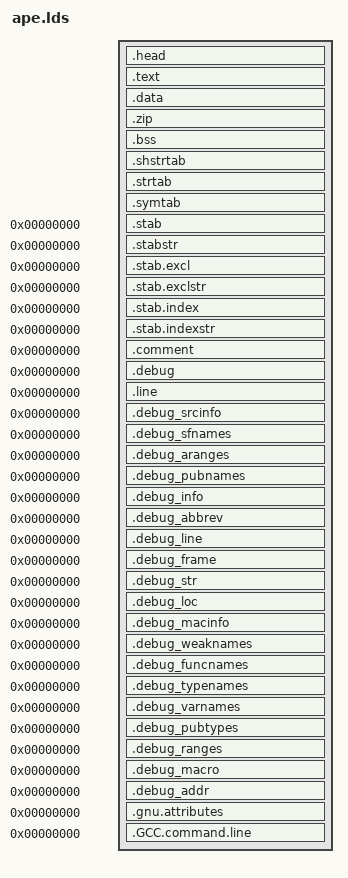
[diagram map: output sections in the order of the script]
ENTRY(_start)
PHDRS {
  Head PT_LOAD FLAGS(5);
  Rom PT_LOAD FLAGS(5);
  Ram PT_LOAD FLAGS(6);
  stack PT_GNU_STACK FLAGS(6);
}
SECTIONS {
  .head SEGMENT_START("text-segment", 0x400000) : AT(0x2000) {
    HIDDEN(_base = .);
    KEEP(*(.head))
    KEEP(*(.text.head))
    . = ALIGN(8);
    HIDDEN(ape_phdrs = .);
    KEEP(*(.elf.phdrs))
    HIDDEN(ape_phdrs_end = .);
    . = ALIGN(8);
    HIDDEN(ape_note = .);
    KEEP(*(.note.openbsd.ident))
    KEEP(*(.note.netbsd.ident))
    HIDDEN(ape_note_end = .);
    KEEP(*(.pe.header))
    HIDDEN(ape_pe_sections = .);
    KEEP(*(.pe.sections))
    HIDDEN(ape_pe_sections_end = .);
    KEEP(*(.macho))
    . = ALIGN(8);
    HIDDEN(ape_macho_end = .);
    KEEP(*(.ape.pad.head))
    . = ALIGN(((255 & 4) == 4) || ((255 & 2) == 2) ? 0x1000 : 16);
    HIDDEN(_ehead = .);
  } :Head
  .text . : {
    *(.text.real)
    KEEP(*(SORT_BY_NAME(.sort.text.real.*)))
    HIDDEN(_ereal = .);
    . += 1;
    *(.start)
    KEEP(*(.initprologue))
    KEEP(*(SORT_BY_NAME(.init.*)))
    KEEP(*(.init))
    KEEP(*(.initepilogue))
    KEEP(*(.pltprologue))
    *(.plt)
    KEEP(*(.pltepilogue))
    KEEP(*(.pltgotprologue))
    *(.plt.got)
    KEEP(*(.pltgotepilogue))
    *(.text.startup .text.startup.*)
    *(.text.exit .text.exit.*)
    *(.text.unlikely .text.*_unlikely .text.unlikely.*)
    *(SORT_BY_ALIGNMENT(.text.antiquity))
    *(SORT_BY_ALIGNMENT(.text.antiquity.*))
    KEEP(*(.textwindowsprologue))
    *(.text.windows)
    KEEP(*(.textwindowsepilogue))
    *(SORT_BY_ALIGNMENT(.text.modernity))
    *(SORT_BY_ALIGNMENT(.text.modernity.*))
    *(SORT_BY_ALIGNMENT(.text.hot))
    *(SORT_BY_ALIGNMENT(.text.hot.*))
    KEEP(*(.keep.text))
    *(.text .stub .text.*)
    KEEP(*(SORT_BY_NAME(.sort.text.*)))
    KEEP(*(.ape.pad.test));
    *(.test.unlikely)
    *(.test .test.*)
    KEEP(*(.ape.pad.privileged));
    . += . > 0 ? 1 : 0;
    HIDDEN(__privileged_start = .);
    . += . > 0 ? 1 : 0;
    *(.privileged)
    HIDDEN(__privileged_end = .);
    . += . > 0 ? 1 : 0;
    KEEP(*(.ape.pad.rodata));
    *(.rodata .rodata.*)
    *(.ubsan.types)
    *(.ubsan.data)
    KEEP(*(.commentprologue))
    KEEP(*(.comment))
    KEEP(*(.commentepilogue))
    KEEP(*(.idata.ro));
    KEEP(*(SORT_BY_NAME(.idata.ro.*)))
    . = ALIGN(8);
    PROVIDE_HIDDEN(__init_array_start = .);
    KEEP(*(SORT_BY_INIT_PRIORITY(.init_array.*)
           SORT_BY_INIT_PRIORITY(.ctors.*)))
    KEEP(*(.ctors))
    KEEP(*(.init_array))
    KEEP(*(.preinit_array))
    PROVIDE_HIDDEN(__init_array_end = .);
    . = ALIGN(8);
    PROVIDE_HIDDEN(__fini_array_start = .);
    KEEP(*(SORT_BY_INIT_PRIORITY(.fini_array.*)
           SORT_BY_INIT_PRIORITY(.dtors.*)))
    KEEP(*(.dtors))
    PROVIDE_HIDDEN(__fini_array_end = .);
    KEEP(*(.initroprologue))
    KEEP(*(SORT_BY_NAME(.initro.*)))
    KEEP(*(.initroepilogue))
    KEEP(*(SORT_BY_NAME(.sort.rodata.*)))
    KEEP(*(.ape.pad.text))
    . = ALIGN(0x1000);
    HIDDEN(_etext = .);
    PROVIDE_HIDDEN(etext = .);
  } :Rom
  .data . : {
    KEEP(*(.dataprologue))
    *(.data .data.*)
    KEEP(*(SORT_BY_NAME(.sort.data.*)))
    . += . > 0 ? 1 : 0;
    KEEP(*(.gotprologue))
    *(.got)
    KEEP(*(.gotepilogue))
    KEEP(*(.gotpltprologue))
    *(.got.plt)
    KEEP(*(.gotpltepilogue))
    . = ALIGN(8);
    KEEP(*(SORT_BY_NAME(.piro.relo.sort.*)))
    PROVIDE_HIDDEN(__relo_end = .);
    . = ALIGN(8);
    KEEP(*(SORT_BY_NAME(.piro.data.sort.*)))
    KEEP(*(.piro.pad.data))
    . = ALIGN(0x1000);
    HIDDEN(_edata = .);
    PROVIDE_HIDDEN(edata = .);
  } :Ram
  .zip . : {
    KEEP(*(SORT_BY_NAME(.zip.*)))
    HIDDEN(_ezip = .);
  }
  .bss ALIGN(8) : {
    KEEP(*(SORT_BY_NAME(.piro.bss.init.*)))
    *(.piro.bss)
    KEEP(*(SORT_BY_NAME(.piro.bss.sort.*)))
    HIDDEN(__piro_end = .);
    . += . > 0 ? 1 : 0;
    *(SORT_BY_ALIGNMENT(.bss))
    *(SORT_BY_ALIGNMENT(.bss.*))
    *(COMMON)
    KEEP(*(SORT_BY_NAME(.sort.bss.*)))
    . = ALIGN(0x10000);
    HIDDEN(_end = .);
    PROVIDE_HIDDEN(end = .);
  }
  .shstrtab : { *(.shstrtab) }
  .strtab : { *(.strtab) }
  .symtab : { *(.symtab) }
  .stab 0 : { *(.stab) }
  .stabstr 0 : { *(.stabstr) }
  .stab.excl 0 : { *(.stab.excl) }
  .stab.exclstr 0 : { *(.stab.exclstr) }
  .stab.index 0 : { *(.stab.index) }
  .stab.indexstr 0 : { *(.stab.indexstr) }
  .comment 0 : { *(.comment) }
  .debug 0 : { *(.debug) }
  .line 0 : { *(.line) }
  .debug_srcinfo 0 : { *(.debug_srcinfo) }
  .debug_sfnames 0 : { *(.debug_sfnames) }
  .debug_aranges 0 : { *(.debug_aranges) }
  .debug_pubnames 0 : { *(.debug_pubnames) }
  .debug_info 0 : { *(.debug_info .gnu.linkonce.wi.*) }
  .debug_abbrev 0 : { *(.debug_abbrev) }
  .debug_line 0 : { *(.debug_line .debug_line.* .debug_line_end ) }
  .debug_frame 0 : { *(.debug_frame) }
  .debug_str 0 : { *(.debug_str) }
  .debug_loc 0 : { *(.debug_loc) }
  .debug_macinfo 0 : { *(.debug_macinfo) }
  .debug_weaknames 0 : { *(.debug_weaknames) }
  .debug_funcnames 0 : { *(.debug_funcnames) }
  .debug_typenames 0 : { *(.debug_typenames) }
  .debug_varnames 0 : { *(.debug_varnames) }
  .debug_pubtypes 0 : { *(.debug_pubtypes) }
  .debug_ranges 0 : { *(.debug_ranges) }
  .debug_macro 0 : { *(.debug_macro) }
  .debug_addr 0 : { *(.debug_addr) }
  .gnu.attributes 0 : { KEEP(*(.gnu.attributes)) }
  .GCC.command.line 0 : { *(.GCC.command.line) }
  /DISCARD/ : {
    *(__mcount_loc)
    *(.discard)
    *(.yoink)
    *(.*)
  }
}
HIDDEN(ape_elf_entry = (_start)); HIDDEN(ape_elf_entry_bcs0 = (((((((_start) >> ((0)*8)) >> 0)&0x7) + 0x30) << 24) | ((((((_start) >> ((0)*8)) >> 3)&0x7) + 0x30) << 16) | (((((((_start) >> ((0)*8))&0xff) >> 6)&0x7) + 0x30) << 8) | 0x5c)); HIDDEN(ape_elf_entry_bcs1 = (((((((_start) >> ((1)*8)) >> 0)&0x7) + 0x30) << 24) | ((((((_start) >> ((1)*8)) >> 3)&0x7) + 0x30) << 16) | (((((((_start) >> ((1)*8))&0xff) >> 6)&0x7) + 0x30) << 8) | 0x5c)); HIDDEN(ape_elf_entry_bcs2 = (((((((_start) >> ((2)*8)) >> 0)&0x7) + 0x30) << 24) | ((((((_start) >> ((2)*8)) >> 3)&0x7) + 0x30) << 16) | (((((((_start) >> ((2)*8))&0xff) >> 6)&0x7) + 0x30) << 8) | 0x5c)); HIDDEN(ape_elf_entry_bcs3 = (((((((_start) >> ((3)*8)) >> 0)&0x7) + 0x30) << 24) | ((((((_start) >> ((3)*8)) >> 3)&0x7) + 0x30) << 16) | (((((((_start) >> ((3)*8))&0xff) >> 6)&0x7) + 0x30) << 8) | 0x5c)); HIDDEN(ape_elf_entry_bcs4 = (((((((_start) >> ((4)*8)) >> 0)&0x7) + 0x30) << 24) | ((((((_start) >> ((4)*8)) >> 3)&0x7) + 0x30) << 16) | (((((((_start) >> ((4)*8))&0xff) >> 6)&0x7) + 0x30) << 8) | 0x5c)); HIDDEN(ape_elf_entry_bcs5 = (((((((_start) >> ((5)*8)) >> 0)&0x7) + 0x30) << 24) | ((((((_start) >> ((5)*8)) >> 3)&0x7) + 0x30) << 16) | (((((((_start) >> ((5)*8))&0xff) >> 6)&0x7) + 0x30) << 8) | 0x5c)); HIDDEN(ape_elf_entry_bcs6 = (((((((_start) >> ((6)*8)) >> 0)&0x7) + 0x30) << 24) | ((((((_start) >> ((6)*8)) >> 3)&0x7) + 0x30) << 16) | (((((((_start) >> ((6)*8))&0xff) >> 6)&0x7) + 0x30) << 8) | 0x5c)); HIDDEN(ape_elf_entry_bcs7 = (((((((_start) >> ((7)*8)) >> 0)&0x7) + 0x30) << 24) | ((((((_start) >> ((7)*8)) >> 3)&0x7) + 0x30) << 16) | (((((((_start) >> ((7)*8))&0xff) >> 6)&0x7) + 0x30) << 8) | 0x5c));
HIDDEN(ape_elf_phoff = (((ape_phdrs) - (0x400000)))); HIDDEN(ape_elf_phoff_bcs0 = (((((((((ape_phdrs) - (0x400000))) >> ((0)*8)) >> 0)&0x7) + 0x30) << 24) | ((((((((ape_phdrs) - (0x400000))) >> ((0)*8)) >> 3)&0x7) + 0x30) << 16) | (((((((((ape_phdrs) - (0x400000))) >> ((0)*8))&0xff) >> 6)&0x7) + 0x30) << 8) | 0x5c)); HIDDEN(ape_elf_phoff_bcs1 = (((((((((ape_phdrs) - (0x400000))) >> ((1)*8)) >> 0)&0x7) + 0x30) << 24) | ((((((((ape_phdrs) - (0x400000))) >> ((1)*8)) >> 3)&0x7) + 0x30) << 16) | (((((((((ape_phdrs) - (0x400000))) >> ((1)*8))&0xff) >> 6)&0x7) + 0x30) << 8) | 0x5c)); HIDDEN(ape_elf_phoff_bcs2 = (((((((((ape_phdrs) - (0x400000))) >> ((2)*8)) >> 0)&0x7) + 0x30) << 24) | ((((((((ape_phdrs) - (0x400000))) >> ((2)*8)) >> 3)&0x7) + 0x30) << 16) | (((((((((ape_phdrs) - (0x400000))) >> ((2)*8))&0xff) >> 6)&0x7) + 0x30) << 8) | 0x5c)); HIDDEN(ape_elf_phoff_bcs3 = (((((((((ape_phdrs) - (0x400000))) >> ((3)*8)) >> 0)&0x7) + 0x30) << 24) | ((((((((ape_phdrs) - (0x400000))) >> ((3)*8)) >> 3)&0x7) + 0x30) << 16) | (((((((((ape_phdrs) - (0x400000))) >> ((3)*8))&0xff) >> 6)&0x7) + 0x30) << 8) | 0x5c)); HIDDEN(ape_elf_phoff_bcs4 = (((((((((ape_phdrs) - (0x400000))) >> ((4)*8)) >> 0)&0x7) + 0x30) << 24) | ((((((((ape_phdrs) - (0x400000))) >> ((4)*8)) >> 3)&0x7) + 0x30) << 16) | (((((((((ape_phdrs) - (0x400000))) >> ((4)*8))&0xff) >> 6)&0x7) + 0x30) << 8) | 0x5c)); HIDDEN(ape_elf_phoff_bcs5 = (((((((((ape_phdrs) - (0x400000))) >> ((5)*8)) >> 0)&0x7) + 0x30) << 24) | ((((((((ape_phdrs) - (0x400000))) >> ((5)*8)) >> 3)&0x7) + 0x30) << 16) | (((((((((ape_phdrs) - (0x400000))) >> ((5)*8))&0xff) >> 6)&0x7) + 0x30) << 8) | 0x5c)); HIDDEN(ape_elf_phoff_bcs6 = (((((((((ape_phdrs) - (0x400000))) >> ((6)*8)) >> 0)&0x7) + 0x30) << 24) | ((((((((ape_phdrs) - (0x400000))) >> ((6)*8)) >> 3)&0x7) + 0x30) << 16) | (((((((((ape_phdrs) - (0x400000))) >> ((6)*8))&0xff) >> 6)&0x7) + 0x30) << 8) | 0x5c)); HIDDEN(ape_elf_phoff_bcs7 = (((((((((ape_phdrs) - (0x400000))) >> ((7)*8)) >> 0)&0x7) + 0x30) << 24) | ((((((((ape_phdrs) - (0x400000))) >> ((7)*8)) >> 3)&0x7) + 0x30) << 16) | (((((((((ape_phdrs) - (0x400000))) >> ((7)*8))&0xff) >> 6)&0x7) + 0x30) << 8) | 0x5c));
HIDDEN(ape_elf_shoff = (0)); HIDDEN(ape_elf_shoff_bcs0 = (((((((0) >> ((0)*8)) >> 0)&0x7) + 0x30) << 24) | ((((((0) >> ((0)*8)) >> 3)&0x7) + 0x30) << 16) | (((((((0) >> ((0)*8))&0xff) >> 6)&0x7) + 0x30) << 8) | 0x5c)); HIDDEN(ape_elf_shoff_bcs1 = (((((((0) >> ((1)*8)) >> 0)&0x7) + 0x30) << 24) | ((((((0) >> ((1)*8)) >> 3)&0x7) + 0x30) << 16) | (((((((0) >> ((1)*8))&0xff) >> 6)&0x7) + 0x30) << 8) | 0x5c)); HIDDEN(ape_elf_shoff_bcs2 = (((((((0) >> ((2)*8)) >> 0)&0x7) + 0x30) << 24) | ((((((0) >> ((2)*8)) >> 3)&0x7) + 0x30) << 16) | (((((((0) >> ((2)*8))&0xff) >> 6)&0x7) + 0x30) << 8) | 0x5c)); HIDDEN(ape_elf_shoff_bcs3 = (((((((0) >> ((3)*8)) >> 0)&0x7) + 0x30) << 24) | ((((((0) >> ((3)*8)) >> 3)&0x7) + 0x30) << 16) | (((((((0) >> ((3)*8))&0xff) >> 6)&0x7) + 0x30) << 8) | 0x5c)); HIDDEN(ape_elf_shoff_bcs4 = (((((((0) >> ((4)*8)) >> 0)&0x7) + 0x30) << 24) | ((((((0) >> ((4)*8)) >> 3)&0x7) + 0x30) << 16) | (((((((0) >> ((4)*8))&0xff) >> 6)&0x7) + 0x30) << 8) | 0x5c)); HIDDEN(ape_elf_shoff_bcs5 = (((((((0) >> ((5)*8)) >> 0)&0x7) + 0x30) << 24) | ((((((0) >> ((5)*8)) >> 3)&0x7) + 0x30) << 16) | (((((((0) >> ((5)*8))&0xff) >> 6)&0x7) + 0x30) << 8) | 0x5c)); HIDDEN(ape_elf_shoff_bcs6 = (((((((0) >> ((6)*8)) >> 0)&0x7) + 0x30) << 24) | ((((((0) >> ((6)*8)) >> 3)&0x7) + 0x30) << 16) | (((((((0) >> ((6)*8))&0xff) >> 6)&0x7) + 0x30) << 8) | 0x5c)); HIDDEN(ape_elf_shoff_bcs7 = (((((((0) >> ((7)*8)) >> 0)&0x7) + 0x30) << 24) | ((((((0) >> ((7)*8)) >> 3)&0x7) + 0x30) << 16) | (((((((0) >> ((7)*8))&0xff) >> 6)&0x7) + 0x30) << 8) | 0x5c));
HIDDEN(ape_elf_phnum = ((ape_phdrs_end - ape_phdrs) / 56)); HIDDEN(ape_elf_phnum_bcs0 = ((((((((ape_phdrs_end - ape_phdrs) / 56) >> ((0)*8)) >> 0)&0x7) + 0x30) << 24) | (((((((ape_phdrs_end - ape_phdrs) / 56) >> ((0)*8)) >> 3)&0x7) + 0x30) << 16) | ((((((((ape_phdrs_end - ape_phdrs) / 56) >> ((0)*8))&0xff) >> 6)&0x7) + 0x30) << 8) | 0x5c)); HIDDEN(ape_elf_phnum_bcs1 = ((((((((ape_phdrs_end - ape_phdrs) / 56) >> ((1)*8)) >> 0)&0x7) + 0x30) << 24) | (((((((ape_phdrs_end - ape_phdrs) / 56) >> ((1)*8)) >> 3)&0x7) + 0x30) << 16) | ((((((((ape_phdrs_end - ape_phdrs) / 56) >> ((1)*8))&0xff) >> 6)&0x7) + 0x30) << 8) | 0x5c)); HIDDEN(ape_elf_phnum_bcs2 = ((((((((ape_phdrs_end - ape_phdrs) / 56) >> ((2)*8)) >> 0)&0x7) + 0x30) << 24) | (((((((ape_phdrs_end - ape_phdrs) / 56) >> ((2)*8)) >> 3)&0x7) + 0x30) << 16) | ((((((((ape_phdrs_end - ape_phdrs) / 56) >> ((2)*8))&0xff) >> 6)&0x7) + 0x30) << 8) | 0x5c)); HIDDEN(ape_elf_phnum_bcs3 = ((((((((ape_phdrs_end - ape_phdrs) / 56) >> ((3)*8)) >> 0)&0x7) + 0x30) << 24) | (((((((ape_phdrs_end - ape_phdrs) / 56) >> ((3)*8)) >> 3)&0x7) + 0x30) << 16) | ((((((((ape_phdrs_end - ape_phdrs) / 56) >> ((3)*8))&0xff) >> 6)&0x7) + 0x30) << 8) | 0x5c));
HIDDEN(ape_elf_shnum = (0)); HIDDEN(ape_elf_shnum_bcs0 = (((((((0) >> ((0)*8)) >> 0)&0x7) + 0x30) << 24) | ((((((0) >> ((0)*8)) >> 3)&0x7) + 0x30) << 16) | (((((((0) >> ((0)*8))&0xff) >> 6)&0x7) + 0x30) << 8) | 0x5c)); HIDDEN(ape_elf_shnum_bcs1 = (((((((0) >> ((1)*8)) >> 0)&0x7) + 0x30) << 24) | ((((((0) >> ((1)*8)) >> 3)&0x7) + 0x30) << 16) | (((((((0) >> ((1)*8))&0xff) >> 6)&0x7) + 0x30) << 8) | 0x5c)); HIDDEN(ape_elf_shnum_bcs2 = (((((((0) >> ((2)*8)) >> 0)&0x7) + 0x30) << 24) | ((((((0) >> ((2)*8)) >> 3)&0x7) + 0x30) << 16) | (((((((0) >> ((2)*8))&0xff) >> 6)&0x7) + 0x30) << 8) | 0x5c)); HIDDEN(ape_elf_shnum_bcs3 = (((((((0) >> ((3)*8)) >> 0)&0x7) + 0x30) << 24) | ((((((0) >> ((3)*8)) >> 3)&0x7) + 0x30) << 16) | (((((((0) >> ((3)*8))&0xff) >> 6)&0x7) + 0x30) << 8) | 0x5c));
HIDDEN(ape_elf_shstrndx = (0)); HIDDEN(ape_elf_shstrndx_bcs0 = (((((((0) >> ((0)*8)) >> 0)&0x7) + 0x30) << 24) | ((((((0) >> ((0)*8)) >> 3)&0x7) + 0x30) << 16) | (((((((0) >> ((0)*8))&0xff) >> 6)&0x7) + 0x30) << 8) | 0x5c)); HIDDEN(ape_elf_shstrndx_bcs1 = (((((((0) >> ((1)*8)) >> 0)&0x7) + 0x30) << 24) | ((((((0) >> ((1)*8)) >> 3)&0x7) + 0x30) << 16) | (((((((0) >> ((1)*8))&0xff) >> 6)&0x7) + 0x30) << 8) | 0x5c)); HIDDEN(ape_elf_shstrndx_bcs2 = (((((((0) >> ((2)*8)) >> 0)&0x7) + 0x30) << 24) | ((((((0) >> ((2)*8)) >> 3)&0x7) + 0x30) << 16) | (((((((0) >> ((2)*8))&0xff) >> 6)&0x7) + 0x30) << 8) | 0x5c)); HIDDEN(ape_elf_shstrndx_bcs3 = (((((((0) >> ((3)*8)) >> 0)&0x7) + 0x30) << 24) | ((((((0) >> ((3)*8)) >> 3)&0x7) + 0x30) << 16) | (((((((0) >> ((3)*8))&0xff) >> 6)&0x7) + 0x30) << 8) | 0x5c));
HIDDEN(__privileged_addr = ((__privileged_start) & -(0x1000)));
HIDDEN(__privileged_size = ((((__privileged_end) + (0x1000)-1) & -(0x1000)) -
                            ((__privileged_start) & -(0x1000))));
HIDDEN(ape_rom_offset = 0);
HIDDEN(ape_rom_vaddr = ADDR(.head));
HIDDEN(ape_rom_paddr = LOADADDR(.head));
HIDDEN(ape_rom_filesz = LOADADDR(.data) - ape_rom_paddr);
HIDDEN(ape_rom_memsz = ADDR(.data) - ADDR(.head));
HIDDEN(ape_rom_align = 0x1000);
HIDDEN(ape_rom_rva = ((ape_rom_vaddr) - (0x400000)));
HIDDEN(ape_ram_offset = ape_rom_offset + ape_rom_filesz);
HIDDEN(ape_ram_vaddr = ADDR(.data));
HIDDEN(ape_ram_paddr = LOADADDR(.data));
HIDDEN(ape_ram_filesz = SIZEOF(.data));
HIDDEN(ape_ram_memsz = ADDR(.bss) + SIZEOF(.bss) - ape_ram_vaddr);
HIDDEN(ape_ram_align = 0x1000);
HIDDEN(ape_ram_rva = ((ape_ram_vaddr) - (0x400000)));
HIDDEN(ape_stack_offset = ape_ram_offset + ape_ram_filesz);
HIDDEN(ape_stack_vaddr = 0x700000000000 - 0x100000);
HIDDEN(ape_stack_paddr = ape_ram_paddr + ape_ram_filesz);
HIDDEN(ape_stack_filesz = 0);
HIDDEN(ape_stack_memsz = 0x100000);
HIDDEN(ape_stack_align = 16);
HIDDEN(ape_note_offset = ape_rom_offset + (ape_note - ape_rom_vaddr));
HIDDEN(ape_note_vaddr = ape_note);
HIDDEN(ape_note_paddr = ape_rom_paddr + ape_note_offset);
HIDDEN(ape_note_filesz = ape_note_end - ape_note);
HIDDEN(ape_note_memsz = ape_note_filesz);
HIDDEN(ape_note_align = 8);
HIDDEN(ape_text_offset = ape_rom_offset + LOADADDR(.text) - ape_rom_paddr);
HIDDEN(ape_text_paddr = LOADADDR(.text));
HIDDEN(ape_text_vaddr = ADDR(.text));
HIDDEN(ape_text_filesz = SIZEOF(.text));
HIDDEN(ape_text_memsz = SIZEOF(.text));
HIDDEN(ape_text_align = 0x1000);
HIDDEN(ape_text_rva = ((ape_text_vaddr) - (0x400000)));
HIDDEN(ape_data_offset = ape_ram_offset + LOADADDR(.data) - ape_ram_paddr);
HIDDEN(ape_data_paddr = LOADADDR(.data));
HIDDEN(ape_data_vaddr = ADDR(.data));
HIDDEN(ape_data_filesz = SIZEOF(.data));
HIDDEN(ape_data_memsz = SIZEOF(.data));
HIDDEN(ape_data_align = 0x1000);
HIDDEN(ape_data_rva = ((ape_data_vaddr) - (0x400000)));
HIDDEN(ape_bss_offset = ape_ram_offset + LOADADDR(.bss) - ape_ram_paddr);
HIDDEN(ape_bss_paddr = LOADADDR(.bss));
HIDDEN(ape_bss_vaddr = ADDR(.bss));
HIDDEN(ape_bss_filesz = 0);
HIDDEN(ape_bss_memsz = SIZEOF(.bss));
HIDDEN(ape_bss_align = 0x1000);
HIDDEN(ape_macho_dd_skip_bcs0 = ((((ape_macho) - (0x400000)) / 8) < 10000 ? 0x20202020 : (((ape_macho) - (0x400000)) / 8) < 100000 ? 0x30202020 + (((((ape_macho) - (0x400000)) / 8) / 10000 % 10) << 24) : (((ape_macho) - (0x400000)) / 8) < 1000000 ? 0x30302020 + (((((ape_macho) - (0x400000)) / 8) / 10000 % 10) << 24) + (((((ape_macho) - (0x400000)) / 8) / 100000 % 10) << 16) : (((ape_macho) - (0x400000)) / 8) < 10000000 ? 0x30303020 + (((((ape_macho) - (0x400000)) / 8) / 10000 % 10) << 24) + (((((ape_macho) - (0x400000)) / 8) / 100000 % 10) << 16) + (((((ape_macho) - (0x400000)) / 8) / 1000000 % 10) << 8) : (((ape_macho) - (0x400000)) / 8) < 100000000 ? 0x30303030 + (((((ape_macho) - (0x400000)) / 8) / 10000 % 10) << 24) + (((((ape_macho) - (0x400000)) / 8) / 100000 % 10) << 16) + (((((ape_macho) - (0x400000)) / 8) / 1000000 % 10) << 8) + (((((ape_macho) - (0x400000)) / 8) / 10000000 % 10) << 0) : 0xffffffffffffffff)); HIDDEN(ape_macho_dd_skip_bcs1 = ((((ape_macho) - (0x400000)) / 8) == 0 ? 0x20202030 : (((ape_macho) - (0x400000)) / 8) < 10 ? 0x30202020 + (((((ape_macho) - (0x400000)) / 8) % 10) << 24) : (((ape_macho) - (0x400000)) / 8) < 100 ? 0x30302020 + (((((ape_macho) - (0x400000)) / 8) % 10) << 24) + (((((ape_macho) - (0x400000)) / 8) / 10 % 10) << 16) : (((ape_macho) - (0x400000)) / 8) < 1000 ? 0x30303020 + (((((ape_macho) - (0x400000)) / 8) % 10) << 24) + (((((ape_macho) - (0x400000)) / 8) / 10 % 10) << 16) + (((((ape_macho) - (0x400000)) / 8) / 100 % 10) << 8) : 0x30303030 + (((((ape_macho) - (0x400000)) / 8) % 10) << 24) + (((((ape_macho) - (0x400000)) / 8) / 10 % 10) << 16) + (((((ape_macho) - (0x400000)) / 8) / 100 % 10) << 8) + (((((ape_macho) - (0x400000)) / 8) / 1000 % 10) << 0)));
HIDDEN(ape_macho_dd_count_bcs0 = (((ape_macho_end - ape_macho) / 8) < 10000 ? 0x20202020 : ((ape_macho_end - ape_macho) / 8) < 100000 ? 0x30202020 + ((((ape_macho_end - ape_macho) / 8) / 10000 % 10) << 24) : ((ape_macho_end - ape_macho) / 8) < 1000000 ? 0x30302020 + ((((ape_macho_end - ape_macho) / 8) / 10000 % 10) << 24) + ((((ape_macho_end - ape_macho) / 8) / 100000 % 10) << 16) : ((ape_macho_end - ape_macho) / 8) < 10000000 ? 0x30303020 + ((((ape_macho_end - ape_macho) / 8) / 10000 % 10) << 24) + ((((ape_macho_end - ape_macho) / 8) / 100000 % 10) << 16) + ((((ape_macho_end - ape_macho) / 8) / 1000000 % 10) << 8) : ((ape_macho_end - ape_macho) / 8) < 100000000 ? 0x30303030 + ((((ape_macho_end - ape_macho) / 8) / 10000 % 10) << 24) + ((((ape_macho_end - ape_macho) / 8) / 100000 % 10) << 16) + ((((ape_macho_end - ape_macho) / 8) / 1000000 % 10) << 8) + ((((ape_macho_end - ape_macho) / 8) / 10000000 % 10) << 0) : 0xffffffffffffffff)); HIDDEN(ape_macho_dd_count_bcs1 = (((ape_macho_end - ape_macho) / 8) == 0 ? 0x20202030 : ((ape_macho_end - ape_macho) / 8) < 10 ? 0x30202020 + ((((ape_macho_end - ape_macho) / 8) % 10) << 24) : ((ape_macho_end - ape_macho) / 8) < 100 ? 0x30302020 + ((((ape_macho_end - ape_macho) / 8) % 10) << 24) + ((((ape_macho_end - ape_macho) / 8) / 10 % 10) << 16) : ((ape_macho_end - ape_macho) / 8) < 1000 ? 0x30303020 + ((((ape_macho_end - ape_macho) / 8) % 10) << 24) + ((((ape_macho_end - ape_macho) / 8) / 10 % 10) << 16) + ((((ape_macho_end - ape_macho) / 8) / 100 % 10) << 8) : 0x30303030 + ((((ape_macho_end - ape_macho) / 8) % 10) << 24) + ((((ape_macho_end - ape_macho) / 8) / 10 % 10) << 16) + ((((ape_macho_end - ape_macho) / 8) / 100 % 10) << 8) + ((((ape_macho_end - ape_macho) / 8) / 1000 % 10) << 0)));
HIDDEN(ape_pe_offset = (ape_pe - ape_mz)); HIDDEN(ape_pe_offset_bcs0 = (((((((ape_pe - ape_mz) >> ((0)*8)) >> 0)&0x7) + 0x30) << 24) | ((((((ape_pe - ape_mz) >> ((0)*8)) >> 3)&0x7) + 0x30) << 16) | (((((((ape_pe - ape_mz) >> ((0)*8))&0xff) >> 6)&0x7) + 0x30) << 8) | 0x5c)); HIDDEN(ape_pe_offset_bcs1 = (((((((ape_pe - ape_mz) >> ((1)*8)) >> 0)&0x7) + 0x30) << 24) | ((((((ape_pe - ape_mz) >> ((1)*8)) >> 3)&0x7) + 0x30) << 16) | (((((((ape_pe - ape_mz) >> ((1)*8))&0xff) >> 6)&0x7) + 0x30) << 8) | 0x5c)); HIDDEN(ape_pe_offset_bcs2 = (((((((ape_pe - ape_mz) >> ((2)*8)) >> 0)&0x7) + 0x30) << 24) | ((((((ape_pe - ape_mz) >> ((2)*8)) >> 3)&0x7) + 0x30) << 16) | (((((((ape_pe - ape_mz) >> ((2)*8))&0xff) >> 6)&0x7) + 0x30) << 8) | 0x5c)); HIDDEN(ape_pe_offset_bcs3 = (((((((ape_pe - ape_mz) >> ((3)*8)) >> 0)&0x7) + 0x30) << 24) | ((((((ape_pe - ape_mz) >> ((3)*8)) >> 3)&0x7) + 0x30) << 16) | (((((((ape_pe - ape_mz) >> ((3)*8))&0xff) >> 6)&0x7) + 0x30) << 8) | 0x5c));
HIDDEN(ape_pe_optsz = ape_pe_sections - (ape_pe + 24));
HIDDEN(ape_pe_shnum = (ape_pe_sections_end - ape_pe_sections) / 40);
HIDDEN(ape_pe_base = 0x400000);
HIDDEN(ape_idata = (((255 & 4) == 4) && !DEFINED(EfiMain)) ? ((ape_idata_iat) - (0x400000)) : 0);
HIDDEN(ape_idata_iatsize = (((255 & 4) == 4) && !DEFINED(EfiMain)) ? ape_idata_iatend - ape_idata_iat : 0);
HIDDEN(ape_idata = (((255 & 4) == 4) && !DEFINED(EfiMain)) ? ((ape_idata_idt) - (0x400000)) : 0);
HIDDEN(ape_idata_idtsize = (((255 & 4) == 4) && !DEFINED(EfiMain)) ? ape_idata_idtend - ape_idata_idt : 0);
HIDDEN(v_ntversion = (((255 & 4) == 4) && !DEFINED(EfiMain)) ? 6 : 1);
HIDDEN(v_ntdllchar = (((255 & 4) == 4) && !DEFINED(EfiMain)) ? 288 : 0);
HIDDEN(v_ntsubversion = (((255 & 4) == 4) && !DEFINED(EfiMain)) ? 6 : 5);
HIDDEN(v_ntsubsystem = ((((255 & 4) == 4) && !DEFINED(EfiMain))
                        ? (DEFINED(GetMessage)
                           ? 2
                           : 3)
                        : 10));
HIDDEN(ape_pe_entry = (((255 & 4) == 4) && !DEFINED(EfiMain)) ? WinMain : EfiMain);
HIDDEN(v_ape_realsectors =
           (((((((_edata) - (0x400000))) + (4096)-1) & -(4096))) > (0x70000 - 0x2000) ? (0x70000 - 0x2000) : ((((((_edata) - (0x400000))) + (4096)-1) & -(4096)))) / 512);
HIDDEN(v_ape_realpages = v_ape_realsectors / (4096 / 512));
HIDDEN(v_ape_highsectors =
           ((((((_edata) - (0x400000))) + (512)-1) & -(512)) / 512) - v_ape_realsectors);
HIDDEN(v_zip_cdoffset = DEFINED(__zip_start) ? __zip_start - 0x400000 : 0);;
HIDDEN(v_zip_cdirsize = DEFINED(__zip_start) ? __zip_end - __zip_start : 0);;
ASSERT(v_zip_cdirsize % (((46 + 248) + (2)-1) & -(2)) == 0, "bad zip cdir");
HIDDEN(v_zip_records = DEFINED(__zip_start) ? v_zip_cdirsize / (((46 + 248) + (2)-1) & -(2)) : 0);;
HIDDEN(v_zip_commentsize = DEFINED(__zip_start) ? _ezip - __zip_end - 22 : 0);;
HIDDEN(ape_uuid1 = 88172645463325252);
HIDDEN(ape_uuid2 = 88172645463325252);
ape_uuid1 = ((ape_uuid1 | (ape_bss_align >> 12)) - (ape_uuid1 & (ape_bss_align >> 12))); ape_uuid1 = ((ape_uuid1 | (ape_bss_align << 25)) - (ape_uuid1 & (ape_bss_align << 25))); ape_uuid1 = ((ape_uuid1 | (ape_bss_align >> 27)) - (ape_uuid1 & (ape_bss_align >> 27))); ape_uuid1 = (ape_uuid1 + (ape_bss_align >> 000) & 0xFF) * 0x9e3779b9925d4c17; ape_uuid1 = (ape_uuid1 + (ape_bss_align >> 010) & 0xFF) * 0x9e3779b9925d4c17; ape_uuid1 = (ape_uuid1 + (ape_bss_align >> 020) & 0xFF) * 0x9e3779b9925d4c17; ape_uuid1 = (ape_uuid1 + (ape_bss_align >> 030) & 0xFF) * 0x9e3779b9925d4c17; ape_uuid2 = ((ape_uuid2 | (ape_bss_align >> 12)) - (ape_uuid2 & (ape_bss_align >> 12))); ape_uuid2 = ((ape_uuid2 | (ape_bss_align << 25)) - (ape_uuid2 & (ape_bss_align << 25))); ape_uuid2 = ((ape_uuid2 | (ape_bss_align >> 27)) - (ape_uuid2 & (ape_bss_align >> 27))); ape_uuid2 = (ape_uuid2 + (ape_bss_align >> 000) & 0xFF) * 0x9e3779b9925d4c17; ape_uuid2 = (ape_uuid2 + (ape_bss_align >> 010) & 0xFF) * 0x9e3779b9925d4c17; ape_uuid2 = (ape_uuid2 + (ape_bss_align >> 020) & 0xFF) * 0x9e3779b9925d4c17; ape_uuid2 = (ape_uuid2 + (ape_bss_align >> 030) & 0xFF) * 0x9e3779b9925d4c17;
ape_uuid1 = ((ape_uuid1 | (ape_bss_filesz >> 12)) - (ape_uuid1 & (ape_bss_filesz >> 12))); ape_uuid1 = ((ape_uuid1 | (ape_bss_filesz << 25)) - (ape_uuid1 & (ape_bss_filesz << 25))); ape_uuid1 = ((ape_uuid1 | (ape_bss_filesz >> 27)) - (ape_uuid1 & (ape_bss_filesz >> 27))); ape_uuid1 = (ape_uuid1 + (ape_bss_filesz >> 000) & 0xFF) * 0x9e3779b9925d4c17; ape_uuid1 = (ape_uuid1 + (ape_bss_filesz >> 010) & 0xFF) * 0x9e3779b9925d4c17; ape_uuid1 = (ape_uuid1 + (ape_bss_filesz >> 020) & 0xFF) * 0x9e3779b9925d4c17; ape_uuid1 = (ape_uuid1 + (ape_bss_filesz >> 030) & 0xFF) * 0x9e3779b9925d4c17; ape_uuid2 = ((ape_uuid2 | (ape_bss_filesz >> 12)) - (ape_uuid2 & (ape_bss_filesz >> 12))); ape_uuid2 = ((ape_uuid2 | (ape_bss_filesz << 25)) - (ape_uuid2 & (ape_bss_filesz << 25))); ape_uuid2 = ((ape_uuid2 | (ape_bss_filesz >> 27)) - (ape_uuid2 & (ape_bss_filesz >> 27))); ape_uuid2 = (ape_uuid2 + (ape_bss_filesz >> 000) & 0xFF) * 0x9e3779b9925d4c17; ape_uuid2 = (ape_uuid2 + (ape_bss_filesz >> 010) & 0xFF) * 0x9e3779b9925d4c17; ape_uuid2 = (ape_uuid2 + (ape_bss_filesz >> 020) & 0xFF) * 0x9e3779b9925d4c17; ape_uuid2 = (ape_uuid2 + (ape_bss_filesz >> 030) & 0xFF) * 0x9e3779b9925d4c17;
ape_uuid1 = ((ape_uuid1 | (ape_bss_memsz >> 12)) - (ape_uuid1 & (ape_bss_memsz >> 12))); ape_uuid1 = ((ape_uuid1 | (ape_bss_memsz << 25)) - (ape_uuid1 & (ape_bss_memsz << 25))); ape_uuid1 = ((ape_uuid1 | (ape_bss_memsz >> 27)) - (ape_uuid1 & (ape_bss_memsz >> 27))); ape_uuid1 = (ape_uuid1 + (ape_bss_memsz >> 000) & 0xFF) * 0x9e3779b9925d4c17; ape_uuid1 = (ape_uuid1 + (ape_bss_memsz >> 010) & 0xFF) * 0x9e3779b9925d4c17; ape_uuid1 = (ape_uuid1 + (ape_bss_memsz >> 020) & 0xFF) * 0x9e3779b9925d4c17; ape_uuid1 = (ape_uuid1 + (ape_bss_memsz >> 030) & 0xFF) * 0x9e3779b9925d4c17; ape_uuid2 = ((ape_uuid2 | (ape_bss_memsz >> 12)) - (ape_uuid2 & (ape_bss_memsz >> 12))); ape_uuid2 = ((ape_uuid2 | (ape_bss_memsz << 25)) - (ape_uuid2 & (ape_bss_memsz << 25))); ape_uuid2 = ((ape_uuid2 | (ape_bss_memsz >> 27)) - (ape_uuid2 & (ape_bss_memsz >> 27))); ape_uuid2 = (ape_uuid2 + (ape_bss_memsz >> 000) & 0xFF) * 0x9e3779b9925d4c17; ape_uuid2 = (ape_uuid2 + (ape_bss_memsz >> 010) & 0xFF) * 0x9e3779b9925d4c17; ape_uuid2 = (ape_uuid2 + (ape_bss_memsz >> 020) & 0xFF) * 0x9e3779b9925d4c17; ape_uuid2 = (ape_uuid2 + (ape_bss_memsz >> 030) & 0xFF) * 0x9e3779b9925d4c17;
ape_uuid1 = ((ape_uuid1 | (ape_bss_offset >> 12)) - (ape_uuid1 & (ape_bss_offset >> 12))); ape_uuid1 = ((ape_uuid1 | (ape_bss_offset << 25)) - (ape_uuid1 & (ape_bss_offset << 25))); ape_uuid1 = ((ape_uuid1 | (ape_bss_offset >> 27)) - (ape_uuid1 & (ape_bss_offset >> 27))); ape_uuid1 = (ape_uuid1 + (ape_bss_offset >> 000) & 0xFF) * 0x9e3779b9925d4c17; ape_uuid1 = (ape_uuid1 + (ape_bss_offset >> 010) & 0xFF) * 0x9e3779b9925d4c17; ape_uuid1 = (ape_uuid1 + (ape_bss_offset >> 020) & 0xFF) * 0x9e3779b9925d4c17; ape_uuid1 = (ape_uuid1 + (ape_bss_offset >> 030) & 0xFF) * 0x9e3779b9925d4c17; ape_uuid2 = ((ape_uuid2 | (ape_bss_offset >> 12)) - (ape_uuid2 & (ape_bss_offset >> 12))); ape_uuid2 = ((ape_uuid2 | (ape_bss_offset << 25)) - (ape_uuid2 & (ape_bss_offset << 25))); ape_uuid2 = ((ape_uuid2 | (ape_bss_offset >> 27)) - (ape_uuid2 & (ape_bss_offset >> 27))); ape_uuid2 = (ape_uuid2 + (ape_bss_offset >> 000) & 0xFF) * 0x9e3779b9925d4c17; ape_uuid2 = (ape_uuid2 + (ape_bss_offset >> 010) & 0xFF) * 0x9e3779b9925d4c17; ape_uuid2 = (ape_uuid2 + (ape_bss_offset >> 020) & 0xFF) * 0x9e3779b9925d4c17; ape_uuid2 = (ape_uuid2 + (ape_bss_offset >> 030) & 0xFF) * 0x9e3779b9925d4c17;
ape_uuid1 = ((ape_uuid1 | (ape_bss_paddr >> 12)) - (ape_uuid1 & (ape_bss_paddr >> 12))); ape_uuid1 = ((ape_uuid1 | (ape_bss_paddr << 25)) - (ape_uuid1 & (ape_bss_paddr << 25))); ape_uuid1 = ((ape_uuid1 | (ape_bss_paddr >> 27)) - (ape_uuid1 & (ape_bss_paddr >> 27))); ape_uuid1 = (ape_uuid1 + (ape_bss_paddr >> 000) & 0xFF) * 0x9e3779b9925d4c17; ape_uuid1 = (ape_uuid1 + (ape_bss_paddr >> 010) & 0xFF) * 0x9e3779b9925d4c17; ape_uuid1 = (ape_uuid1 + (ape_bss_paddr >> 020) & 0xFF) * 0x9e3779b9925d4c17; ape_uuid1 = (ape_uuid1 + (ape_bss_paddr >> 030) & 0xFF) * 0x9e3779b9925d4c17; ape_uuid2 = ((ape_uuid2 | (ape_bss_paddr >> 12)) - (ape_uuid2 & (ape_bss_paddr >> 12))); ape_uuid2 = ((ape_uuid2 | (ape_bss_paddr << 25)) - (ape_uuid2 & (ape_bss_paddr << 25))); ape_uuid2 = ((ape_uuid2 | (ape_bss_paddr >> 27)) - (ape_uuid2 & (ape_bss_paddr >> 27))); ape_uuid2 = (ape_uuid2 + (ape_bss_paddr >> 000) & 0xFF) * 0x9e3779b9925d4c17; ape_uuid2 = (ape_uuid2 + (ape_bss_paddr >> 010) & 0xFF) * 0x9e3779b9925d4c17; ape_uuid2 = (ape_uuid2 + (ape_bss_paddr >> 020) & 0xFF) * 0x9e3779b9925d4c17; ape_uuid2 = (ape_uuid2 + (ape_bss_paddr >> 030) & 0xFF) * 0x9e3779b9925d4c17;
ape_uuid1 = ((ape_uuid1 | (ape_data_filesz >> 12)) - (ape_uuid1 & (ape_data_filesz >> 12))); ape_uuid1 = ((ape_uuid1 | (ape_data_filesz << 25)) - (ape_uuid1 & (ape_data_filesz << 25))); ape_uuid1 = ((ape_uuid1 | (ape_data_filesz >> 27)) - (ape_uuid1 & (ape_data_filesz >> 27))); ape_uuid1 = (ape_uuid1 + (ape_data_filesz >> 000) & 0xFF) * 0x9e3779b9925d4c17; ape_uuid1 = (ape_uuid1 + (ape_data_filesz >> 010) & 0xFF) * 0x9e3779b9925d4c17; ape_uuid1 = (ape_uuid1 + (ape_data_filesz >> 020) & 0xFF) * 0x9e3779b9925d4c17; ape_uuid1 = (ape_uuid1 + (ape_data_filesz >> 030) & 0xFF) * 0x9e3779b9925d4c17; ape_uuid2 = ((ape_uuid2 | (ape_data_filesz >> 12)) - (ape_uuid2 & (ape_data_filesz >> 12))); ape_uuid2 = ((ape_uuid2 | (ape_data_filesz << 25)) - (ape_uuid2 & (ape_data_filesz << 25))); ape_uuid2 = ((ape_uuid2 | (ape_data_filesz >> 27)) - (ape_uuid2 & (ape_data_filesz >> 27))); ape_uuid2 = (ape_uuid2 + (ape_data_filesz >> 000) & 0xFF) * 0x9e3779b9925d4c17; ape_uuid2 = (ape_uuid2 + (ape_data_filesz >> 010) & 0xFF) * 0x9e3779b9925d4c17; ape_uuid2 = (ape_uuid2 + (ape_data_filesz >> 020) & 0xFF) * 0x9e3779b9925d4c17; ape_uuid2 = (ape_uuid2 + (ape_data_filesz >> 030) & 0xFF) * 0x9e3779b9925d4c17;
ape_uuid1 = ((ape_uuid1 | (ape_data_memsz >> 12)) - (ape_uuid1 & (ape_data_memsz >> 12))); ape_uuid1 = ((ape_uuid1 | (ape_data_memsz << 25)) - (ape_uuid1 & (ape_data_memsz << 25))); ape_uuid1 = ((ape_uuid1 | (ape_data_memsz >> 27)) - (ape_uuid1 & (ape_data_memsz >> 27))); ape_uuid1 = (ape_uuid1 + (ape_data_memsz >> 000) & 0xFF) * 0x9e3779b9925d4c17; ape_uuid1 = (ape_uuid1 + (ape_data_memsz >> 010) & 0xFF) * 0x9e3779b9925d4c17; ape_uuid1 = (ape_uuid1 + (ape_data_memsz >> 020) & 0xFF) * 0x9e3779b9925d4c17; ape_uuid1 = (ape_uuid1 + (ape_data_memsz >> 030) & 0xFF) * 0x9e3779b9925d4c17; ape_uuid2 = ((ape_uuid2 | (ape_data_memsz >> 12)) - (ape_uuid2 & (ape_data_memsz >> 12))); ape_uuid2 = ((ape_uuid2 | (ape_data_memsz << 25)) - (ape_uuid2 & (ape_data_memsz << 25))); ape_uuid2 = ((ape_uuid2 | (ape_data_memsz >> 27)) - (ape_uuid2 & (ape_data_memsz >> 27))); ape_uuid2 = (ape_uuid2 + (ape_data_memsz >> 000) & 0xFF) * 0x9e3779b9925d4c17; ape_uuid2 = (ape_uuid2 + (ape_data_memsz >> 010) & 0xFF) * 0x9e3779b9925d4c17; ape_uuid2 = (ape_uuid2 + (ape_data_memsz >> 020) & 0xFF) * 0x9e3779b9925d4c17; ape_uuid2 = (ape_uuid2 + (ape_data_memsz >> 030) & 0xFF) * 0x9e3779b9925d4c17;
ape_uuid1 = ((ape_uuid1 | (ape_data_offset >> 12)) - (ape_uuid1 & (ape_data_offset >> 12))); ape_uuid1 = ((ape_uuid1 | (ape_data_offset << 25)) - (ape_uuid1 & (ape_data_offset << 25))); ape_uuid1 = ((ape_uuid1 | (ape_data_offset >> 27)) - (ape_uuid1 & (ape_data_offset >> 27))); ape_uuid1 = (ape_uuid1 + (ape_data_offset >> 000) & 0xFF) * 0x9e3779b9925d4c17; ape_uuid1 = (ape_uuid1 + (ape_data_offset >> 010) & 0xFF) * 0x9e3779b9925d4c17; ape_uuid1 = (ape_uuid1 + (ape_data_offset >> 020) & 0xFF) * 0x9e3779b9925d4c17; ape_uuid1 = (ape_uuid1 + (ape_data_offset >> 030) & 0xFF) * 0x9e3779b9925d4c17; ape_uuid2 = ((ape_uuid2 | (ape_data_offset >> 12)) - (ape_uuid2 & (ape_data_offset >> 12))); ape_uuid2 = ((ape_uuid2 | (ape_data_offset << 25)) - (ape_uuid2 & (ape_data_offset << 25))); ape_uuid2 = ((ape_uuid2 | (ape_data_offset >> 27)) - (ape_uuid2 & (ape_data_offset >> 27))); ape_uuid2 = (ape_uuid2 + (ape_data_offset >> 000) & 0xFF) * 0x9e3779b9925d4c17; ape_uuid2 = (ape_uuid2 + (ape_data_offset >> 010) & 0xFF) * 0x9e3779b9925d4c17; ape_uuid2 = (ape_uuid2 + (ape_data_offset >> 020) & 0xFF) * 0x9e3779b9925d4c17; ape_uuid2 = (ape_uuid2 + (ape_data_offset >> 030) & 0xFF) * 0x9e3779b9925d4c17;
ape_uuid1 = ((ape_uuid1 | (ape_data_paddr >> 12)) - (ape_uuid1 & (ape_data_paddr >> 12))); ape_uuid1 = ((ape_uuid1 | (ape_data_paddr << 25)) - (ape_uuid1 & (ape_data_paddr << 25))); ape_uuid1 = ((ape_uuid1 | (ape_data_paddr >> 27)) - (ape_uuid1 & (ape_data_paddr >> 27))); ape_uuid1 = (ape_uuid1 + (ape_data_paddr >> 000) & 0xFF) * 0x9e3779b9925d4c17; ape_uuid1 = (ape_uuid1 + (ape_data_paddr >> 010) & 0xFF) * 0x9e3779b9925d4c17; ape_uuid1 = (ape_uuid1 + (ape_data_paddr >> 020) & 0xFF) * 0x9e3779b9925d4c17; ape_uuid1 = (ape_uuid1 + (ape_data_paddr >> 030) & 0xFF) * 0x9e3779b9925d4c17; ape_uuid2 = ((ape_uuid2 | (ape_data_paddr >> 12)) - (ape_uuid2 & (ape_data_paddr >> 12))); ape_uuid2 = ((ape_uuid2 | (ape_data_paddr << 25)) - (ape_uuid2 & (ape_data_paddr << 25))); ape_uuid2 = ((ape_uuid2 | (ape_data_paddr >> 27)) - (ape_uuid2 & (ape_data_paddr >> 27))); ape_uuid2 = (ape_uuid2 + (ape_data_paddr >> 000) & 0xFF) * 0x9e3779b9925d4c17; ape_uuid2 = (ape_uuid2 + (ape_data_paddr >> 010) & 0xFF) * 0x9e3779b9925d4c17; ape_uuid2 = (ape_uuid2 + (ape_data_paddr >> 020) & 0xFF) * 0x9e3779b9925d4c17; ape_uuid2 = (ape_uuid2 + (ape_data_paddr >> 030) & 0xFF) * 0x9e3779b9925d4c17;
ape_uuid1 = ((ape_uuid1 | (ape_data_rva >> 12)) - (ape_uuid1 & (ape_data_rva >> 12))); ape_uuid1 = ((ape_uuid1 | (ape_data_rva << 25)) - (ape_uuid1 & (ape_data_rva << 25))); ape_uuid1 = ((ape_uuid1 | (ape_data_rva >> 27)) - (ape_uuid1 & (ape_data_rva >> 27))); ape_uuid1 = (ape_uuid1 + (ape_data_rva >> 000) & 0xFF) * 0x9e3779b9925d4c17; ape_uuid1 = (ape_uuid1 + (ape_data_rva >> 010) & 0xFF) * 0x9e3779b9925d4c17; ape_uuid1 = (ape_uuid1 + (ape_data_rva >> 020) & 0xFF) * 0x9e3779b9925d4c17; ape_uuid1 = (ape_uuid1 + (ape_data_rva >> 030) & 0xFF) * 0x9e3779b9925d4c17; ape_uuid2 = ((ape_uuid2 | (ape_data_rva >> 12)) - (ape_uuid2 & (ape_data_rva >> 12))); ape_uuid2 = ((ape_uuid2 | (ape_data_rva << 25)) - (ape_uuid2 & (ape_data_rva << 25))); ape_uuid2 = ((ape_uuid2 | (ape_data_rva >> 27)) - (ape_uuid2 & (ape_data_rva >> 27))); ape_uuid2 = (ape_uuid2 + (ape_data_rva >> 000) & 0xFF) * 0x9e3779b9925d4c17; ape_uuid2 = (ape_uuid2 + (ape_data_rva >> 010) & 0xFF) * 0x9e3779b9925d4c17; ape_uuid2 = (ape_uuid2 + (ape_data_rva >> 020) & 0xFF) * 0x9e3779b9925d4c17; ape_uuid2 = (ape_uuid2 + (ape_data_rva >> 030) & 0xFF) * 0x9e3779b9925d4c17;
ape_uuid1 = ((ape_uuid1 | (ape_data_vaddr >> 12)) - (ape_uuid1 & (ape_data_vaddr >> 12))); ape_uuid1 = ((ape_uuid1 | (ape_data_vaddr << 25)) - (ape_uuid1 & (ape_data_vaddr << 25))); ape_uuid1 = ((ape_uuid1 | (ape_data_vaddr >> 27)) - (ape_uuid1 & (ape_data_vaddr >> 27))); ape_uuid1 = (ape_uuid1 + (ape_data_vaddr >> 000) & 0xFF) * 0x9e3779b9925d4c17; ape_uuid1 = (ape_uuid1 + (ape_data_vaddr >> 010) & 0xFF) * 0x9e3779b9925d4c17; ape_uuid1 = (ape_uuid1 + (ape_data_vaddr >> 020) & 0xFF) * 0x9e3779b9925d4c17; ape_uuid1 = (ape_uuid1 + (ape_data_vaddr >> 030) & 0xFF) * 0x9e3779b9925d4c17; ape_uuid2 = ((ape_uuid2 | (ape_data_vaddr >> 12)) - (ape_uuid2 & (ape_data_vaddr >> 12))); ape_uuid2 = ((ape_uuid2 | (ape_data_vaddr << 25)) - (ape_uuid2 & (ape_data_vaddr << 25))); ape_uuid2 = ((ape_uuid2 | (ape_data_vaddr >> 27)) - (ape_uuid2 & (ape_data_vaddr >> 27))); ape_uuid2 = (ape_uuid2 + (ape_data_vaddr >> 000) & 0xFF) * 0x9e3779b9925d4c17; ape_uuid2 = (ape_uuid2 + (ape_data_vaddr >> 010) & 0xFF) * 0x9e3779b9925d4c17; ape_uuid2 = (ape_uuid2 + (ape_data_vaddr >> 020) & 0xFF) * 0x9e3779b9925d4c17; ape_uuid2 = (ape_uuid2 + (ape_data_vaddr >> 030) & 0xFF) * 0x9e3779b9925d4c17;
ape_uuid1 = ((ape_uuid1 | (ape_elf_entry >> 12)) - (ape_uuid1 & (ape_elf_entry >> 12))); ape_uuid1 = ((ape_uuid1 | (ape_elf_entry << 25)) - (ape_uuid1 & (ape_elf_entry << 25))); ape_uuid1 = ((ape_uuid1 | (ape_elf_entry >> 27)) - (ape_uuid1 & (ape_elf_entry >> 27))); ape_uuid1 = (ape_uuid1 + (ape_elf_entry >> 000) & 0xFF) * 0x9e3779b9925d4c17; ape_uuid1 = (ape_uuid1 + (ape_elf_entry >> 010) & 0xFF) * 0x9e3779b9925d4c17; ape_uuid1 = (ape_uuid1 + (ape_elf_entry >> 020) & 0xFF) * 0x9e3779b9925d4c17; ape_uuid1 = (ape_uuid1 + (ape_elf_entry >> 030) & 0xFF) * 0x9e3779b9925d4c17; ape_uuid2 = ((ape_uuid2 | (ape_elf_entry >> 12)) - (ape_uuid2 & (ape_elf_entry >> 12))); ape_uuid2 = ((ape_uuid2 | (ape_elf_entry << 25)) - (ape_uuid2 & (ape_elf_entry << 25))); ape_uuid2 = ((ape_uuid2 | (ape_elf_entry >> 27)) - (ape_uuid2 & (ape_elf_entry >> 27))); ape_uuid2 = (ape_uuid2 + (ape_elf_entry >> 000) & 0xFF) * 0x9e3779b9925d4c17; ape_uuid2 = (ape_uuid2 + (ape_elf_entry >> 010) & 0xFF) * 0x9e3779b9925d4c17; ape_uuid2 = (ape_uuid2 + (ape_elf_entry >> 020) & 0xFF) * 0x9e3779b9925d4c17; ape_uuid2 = (ape_uuid2 + (ape_elf_entry >> 030) & 0xFF) * 0x9e3779b9925d4c17;
ape_uuid1 = ((ape_uuid1 | (ape_elf_phnum >> 12)) - (ape_uuid1 & (ape_elf_phnum >> 12))); ape_uuid1 = ((ape_uuid1 | (ape_elf_phnum << 25)) - (ape_uuid1 & (ape_elf_phnum << 25))); ape_uuid1 = ((ape_uuid1 | (ape_elf_phnum >> 27)) - (ape_uuid1 & (ape_elf_phnum >> 27))); ape_uuid1 = (ape_uuid1 + (ape_elf_phnum >> 000) & 0xFF) * 0x9e3779b9925d4c17; ape_uuid1 = (ape_uuid1 + (ape_elf_phnum >> 010) & 0xFF) * 0x9e3779b9925d4c17; ape_uuid1 = (ape_uuid1 + (ape_elf_phnum >> 020) & 0xFF) * 0x9e3779b9925d4c17; ape_uuid1 = (ape_uuid1 + (ape_elf_phnum >> 030) & 0xFF) * 0x9e3779b9925d4c17; ape_uuid2 = ((ape_uuid2 | (ape_elf_phnum >> 12)) - (ape_uuid2 & (ape_elf_phnum >> 12))); ape_uuid2 = ((ape_uuid2 | (ape_elf_phnum << 25)) - (ape_uuid2 & (ape_elf_phnum << 25))); ape_uuid2 = ((ape_uuid2 | (ape_elf_phnum >> 27)) - (ape_uuid2 & (ape_elf_phnum >> 27))); ape_uuid2 = (ape_uuid2 + (ape_elf_phnum >> 000) & 0xFF) * 0x9e3779b9925d4c17; ape_uuid2 = (ape_uuid2 + (ape_elf_phnum >> 010) & 0xFF) * 0x9e3779b9925d4c17; ape_uuid2 = (ape_uuid2 + (ape_elf_phnum >> 020) & 0xFF) * 0x9e3779b9925d4c17; ape_uuid2 = (ape_uuid2 + (ape_elf_phnum >> 030) & 0xFF) * 0x9e3779b9925d4c17;
ape_uuid1 = ((ape_uuid1 | (ape_elf_phoff >> 12)) - (ape_uuid1 & (ape_elf_phoff >> 12))); ape_uuid1 = ((ape_uuid1 | (ape_elf_phoff << 25)) - (ape_uuid1 & (ape_elf_phoff << 25))); ape_uuid1 = ((ape_uuid1 | (ape_elf_phoff >> 27)) - (ape_uuid1 & (ape_elf_phoff >> 27))); ape_uuid1 = (ape_uuid1 + (ape_elf_phoff >> 000) & 0xFF) * 0x9e3779b9925d4c17; ape_uuid1 = (ape_uuid1 + (ape_elf_phoff >> 010) & 0xFF) * 0x9e3779b9925d4c17; ape_uuid1 = (ape_uuid1 + (ape_elf_phoff >> 020) & 0xFF) * 0x9e3779b9925d4c17; ape_uuid1 = (ape_uuid1 + (ape_elf_phoff >> 030) & 0xFF) * 0x9e3779b9925d4c17; ape_uuid2 = ((ape_uuid2 | (ape_elf_phoff >> 12)) - (ape_uuid2 & (ape_elf_phoff >> 12))); ape_uuid2 = ((ape_uuid2 | (ape_elf_phoff << 25)) - (ape_uuid2 & (ape_elf_phoff << 25))); ape_uuid2 = ((ape_uuid2 | (ape_elf_phoff >> 27)) - (ape_uuid2 & (ape_elf_phoff >> 27))); ape_uuid2 = (ape_uuid2 + (ape_elf_phoff >> 000) & 0xFF) * 0x9e3779b9925d4c17; ape_uuid2 = (ape_uuid2 + (ape_elf_phoff >> 010) & 0xFF) * 0x9e3779b9925d4c17; ape_uuid2 = (ape_uuid2 + (ape_elf_phoff >> 020) & 0xFF) * 0x9e3779b9925d4c17; ape_uuid2 = (ape_uuid2 + (ape_elf_phoff >> 030) & 0xFF) * 0x9e3779b9925d4c17;
ape_uuid1 = ((ape_uuid1 | (ape_elf_shnum >> 12)) - (ape_uuid1 & (ape_elf_shnum >> 12))); ape_uuid1 = ((ape_uuid1 | (ape_elf_shnum << 25)) - (ape_uuid1 & (ape_elf_shnum << 25))); ape_uuid1 = ((ape_uuid1 | (ape_elf_shnum >> 27)) - (ape_uuid1 & (ape_elf_shnum >> 27))); ape_uuid1 = (ape_uuid1 + (ape_elf_shnum >> 000) & 0xFF) * 0x9e3779b9925d4c17; ape_uuid1 = (ape_uuid1 + (ape_elf_shnum >> 010) & 0xFF) * 0x9e3779b9925d4c17; ape_uuid1 = (ape_uuid1 + (ape_elf_shnum >> 020) & 0xFF) * 0x9e3779b9925d4c17; ape_uuid1 = (ape_uuid1 + (ape_elf_shnum >> 030) & 0xFF) * 0x9e3779b9925d4c17; ape_uuid2 = ((ape_uuid2 | (ape_elf_shnum >> 12)) - (ape_uuid2 & (ape_elf_shnum >> 12))); ape_uuid2 = ((ape_uuid2 | (ape_elf_shnum << 25)) - (ape_uuid2 & (ape_elf_shnum << 25))); ape_uuid2 = ((ape_uuid2 | (ape_elf_shnum >> 27)) - (ape_uuid2 & (ape_elf_shnum >> 27))); ape_uuid2 = (ape_uuid2 + (ape_elf_shnum >> 000) & 0xFF) * 0x9e3779b9925d4c17; ape_uuid2 = (ape_uuid2 + (ape_elf_shnum >> 010) & 0xFF) * 0x9e3779b9925d4c17; ape_uuid2 = (ape_uuid2 + (ape_elf_shnum >> 020) & 0xFF) * 0x9e3779b9925d4c17; ape_uuid2 = (ape_uuid2 + (ape_elf_shnum >> 030) & 0xFF) * 0x9e3779b9925d4c17;
ape_uuid1 = ((ape_uuid1 | (ape_elf_shoff >> 12)) - (ape_uuid1 & (ape_elf_shoff >> 12))); ape_uuid1 = ((ape_uuid1 | (ape_elf_shoff << 25)) - (ape_uuid1 & (ape_elf_shoff << 25))); ape_uuid1 = ((ape_uuid1 | (ape_elf_shoff >> 27)) - (ape_uuid1 & (ape_elf_shoff >> 27))); ape_uuid1 = (ape_uuid1 + (ape_elf_shoff >> 000) & 0xFF) * 0x9e3779b9925d4c17; ape_uuid1 = (ape_uuid1 + (ape_elf_shoff >> 010) & 0xFF) * 0x9e3779b9925d4c17; ape_uuid1 = (ape_uuid1 + (ape_elf_shoff >> 020) & 0xFF) * 0x9e3779b9925d4c17; ape_uuid1 = (ape_uuid1 + (ape_elf_shoff >> 030) & 0xFF) * 0x9e3779b9925d4c17; ape_uuid2 = ((ape_uuid2 | (ape_elf_shoff >> 12)) - (ape_uuid2 & (ape_elf_shoff >> 12))); ape_uuid2 = ((ape_uuid2 | (ape_elf_shoff << 25)) - (ape_uuid2 & (ape_elf_shoff << 25))); ape_uuid2 = ((ape_uuid2 | (ape_elf_shoff >> 27)) - (ape_uuid2 & (ape_elf_shoff >> 27))); ape_uuid2 = (ape_uuid2 + (ape_elf_shoff >> 000) & 0xFF) * 0x9e3779b9925d4c17; ape_uuid2 = (ape_uuid2 + (ape_elf_shoff >> 010) & 0xFF) * 0x9e3779b9925d4c17; ape_uuid2 = (ape_uuid2 + (ape_elf_shoff >> 020) & 0xFF) * 0x9e3779b9925d4c17; ape_uuid2 = (ape_uuid2 + (ape_elf_shoff >> 030) & 0xFF) * 0x9e3779b9925d4c17;
ape_uuid1 = ((ape_uuid1 | (ape_elf_shstrndx >> 12)) - (ape_uuid1 & (ape_elf_shstrndx >> 12))); ape_uuid1 = ((ape_uuid1 | (ape_elf_shstrndx << 25)) - (ape_uuid1 & (ape_elf_shstrndx << 25))); ape_uuid1 = ((ape_uuid1 | (ape_elf_shstrndx >> 27)) - (ape_uuid1 & (ape_elf_shstrndx >> 27))); ape_uuid1 = (ape_uuid1 + (ape_elf_shstrndx >> 000) & 0xFF) * 0x9e3779b9925d4c17; ape_uuid1 = (ape_uuid1 + (ape_elf_shstrndx >> 010) & 0xFF) * 0x9e3779b9925d4c17; ape_uuid1 = (ape_uuid1 + (ape_elf_shstrndx >> 020) & 0xFF) * 0x9e3779b9925d4c17; ape_uuid1 = (ape_uuid1 + (ape_elf_shstrndx >> 030) & 0xFF) * 0x9e3779b9925d4c17; ape_uuid2 = ((ape_uuid2 | (ape_elf_shstrndx >> 12)) - (ape_uuid2 & (ape_elf_shstrndx >> 12))); ape_uuid2 = ((ape_uuid2 | (ape_elf_shstrndx << 25)) - (ape_uuid2 & (ape_elf_shstrndx << 25))); ape_uuid2 = ((ape_uuid2 | (ape_elf_shstrndx >> 27)) - (ape_uuid2 & (ape_elf_shstrndx >> 27))); ape_uuid2 = (ape_uuid2 + (ape_elf_shstrndx >> 000) & 0xFF) * 0x9e3779b9925d4c17; ape_uuid2 = (ape_uuid2 + (ape_elf_shstrndx >> 010) & 0xFF) * 0x9e3779b9925d4c17; ape_uuid2 = (ape_uuid2 + (ape_elf_shstrndx >> 020) & 0xFF) * 0x9e3779b9925d4c17; ape_uuid2 = (ape_uuid2 + (ape_elf_shstrndx >> 030) & 0xFF) * 0x9e3779b9925d4c17;
ape_uuid1 = ((ape_uuid1 | (ape_macho_end >> 12)) - (ape_uuid1 & (ape_macho_end >> 12))); ape_uuid1 = ((ape_uuid1 | (ape_macho_end << 25)) - (ape_uuid1 & (ape_macho_end << 25))); ape_uuid1 = ((ape_uuid1 | (ape_macho_end >> 27)) - (ape_uuid1 & (ape_macho_end >> 27))); ape_uuid1 = (ape_uuid1 + (ape_macho_end >> 000) & 0xFF) * 0x9e3779b9925d4c17; ape_uuid1 = (ape_uuid1 + (ape_macho_end >> 010) & 0xFF) * 0x9e3779b9925d4c17; ape_uuid1 = (ape_uuid1 + (ape_macho_end >> 020) & 0xFF) * 0x9e3779b9925d4c17; ape_uuid1 = (ape_uuid1 + (ape_macho_end >> 030) & 0xFF) * 0x9e3779b9925d4c17; ape_uuid2 = ((ape_uuid2 | (ape_macho_end >> 12)) - (ape_uuid2 & (ape_macho_end >> 12))); ape_uuid2 = ((ape_uuid2 | (ape_macho_end << 25)) - (ape_uuid2 & (ape_macho_end << 25))); ape_uuid2 = ((ape_uuid2 | (ape_macho_end >> 27)) - (ape_uuid2 & (ape_macho_end >> 27))); ape_uuid2 = (ape_uuid2 + (ape_macho_end >> 000) & 0xFF) * 0x9e3779b9925d4c17; ape_uuid2 = (ape_uuid2 + (ape_macho_end >> 010) & 0xFF) * 0x9e3779b9925d4c17; ape_uuid2 = (ape_uuid2 + (ape_macho_end >> 020) & 0xFF) * 0x9e3779b9925d4c17; ape_uuid2 = (ape_uuid2 + (ape_macho_end >> 030) & 0xFF) * 0x9e3779b9925d4c17;
ape_uuid1 = ((ape_uuid1 | (ape_note >> 12)) - (ape_uuid1 & (ape_note >> 12))); ape_uuid1 = ((ape_uuid1 | (ape_note << 25)) - (ape_uuid1 & (ape_note << 25))); ape_uuid1 = ((ape_uuid1 | (ape_note >> 27)) - (ape_uuid1 & (ape_note >> 27))); ape_uuid1 = (ape_uuid1 + (ape_note >> 000) & 0xFF) * 0x9e3779b9925d4c17; ape_uuid1 = (ape_uuid1 + (ape_note >> 010) & 0xFF) * 0x9e3779b9925d4c17; ape_uuid1 = (ape_uuid1 + (ape_note >> 020) & 0xFF) * 0x9e3779b9925d4c17; ape_uuid1 = (ape_uuid1 + (ape_note >> 030) & 0xFF) * 0x9e3779b9925d4c17; ape_uuid2 = ((ape_uuid2 | (ape_note >> 12)) - (ape_uuid2 & (ape_note >> 12))); ape_uuid2 = ((ape_uuid2 | (ape_note << 25)) - (ape_uuid2 & (ape_note << 25))); ape_uuid2 = ((ape_uuid2 | (ape_note >> 27)) - (ape_uuid2 & (ape_note >> 27))); ape_uuid2 = (ape_uuid2 + (ape_note >> 000) & 0xFF) * 0x9e3779b9925d4c17; ape_uuid2 = (ape_uuid2 + (ape_note >> 010) & 0xFF) * 0x9e3779b9925d4c17; ape_uuid2 = (ape_uuid2 + (ape_note >> 020) & 0xFF) * 0x9e3779b9925d4c17; ape_uuid2 = (ape_uuid2 + (ape_note >> 030) & 0xFF) * 0x9e3779b9925d4c17;
ape_uuid1 = ((ape_uuid1 | (ape_note_align >> 12)) - (ape_uuid1 & (ape_note_align >> 12))); ape_uuid1 = ((ape_uuid1 | (ape_note_align << 25)) - (ape_uuid1 & (ape_note_align << 25))); ape_uuid1 = ((ape_uuid1 | (ape_note_align >> 27)) - (ape_uuid1 & (ape_note_align >> 27))); ape_uuid1 = (ape_uuid1 + (ape_note_align >> 000) & 0xFF) * 0x9e3779b9925d4c17; ape_uuid1 = (ape_uuid1 + (ape_note_align >> 010) & 0xFF) * 0x9e3779b9925d4c17; ape_uuid1 = (ape_uuid1 + (ape_note_align >> 020) & 0xFF) * 0x9e3779b9925d4c17; ape_uuid1 = (ape_uuid1 + (ape_note_align >> 030) & 0xFF) * 0x9e3779b9925d4c17; ape_uuid2 = ((ape_uuid2 | (ape_note_align >> 12)) - (ape_uuid2 & (ape_note_align >> 12))); ape_uuid2 = ((ape_uuid2 | (ape_note_align << 25)) - (ape_uuid2 & (ape_note_align << 25))); ape_uuid2 = ((ape_uuid2 | (ape_note_align >> 27)) - (ape_uuid2 & (ape_note_align >> 27))); ape_uuid2 = (ape_uuid2 + (ape_note_align >> 000) & 0xFF) * 0x9e3779b9925d4c17; ape_uuid2 = (ape_uuid2 + (ape_note_align >> 010) & 0xFF) * 0x9e3779b9925d4c17; ape_uuid2 = (ape_uuid2 + (ape_note_align >> 020) & 0xFF) * 0x9e3779b9925d4c17; ape_uuid2 = (ape_uuid2 + (ape_note_align >> 030) & 0xFF) * 0x9e3779b9925d4c17;
ape_uuid1 = ((ape_uuid1 | (ape_note_end >> 12)) - (ape_uuid1 & (ape_note_end >> 12))); ape_uuid1 = ((ape_uuid1 | (ape_note_end << 25)) - (ape_uuid1 & (ape_note_end << 25))); ape_uuid1 = ((ape_uuid1 | (ape_note_end >> 27)) - (ape_uuid1 & (ape_note_end >> 27))); ape_uuid1 = (ape_uuid1 + (ape_note_end >> 000) & 0xFF) * 0x9e3779b9925d4c17; ape_uuid1 = (ape_uuid1 + (ape_note_end >> 010) & 0xFF) * 0x9e3779b9925d4c17; ape_uuid1 = (ape_uuid1 + (ape_note_end >> 020) & 0xFF) * 0x9e3779b9925d4c17; ape_uuid1 = (ape_uuid1 + (ape_note_end >> 030) & 0xFF) * 0x9e3779b9925d4c17; ape_uuid2 = ((ape_uuid2 | (ape_note_end >> 12)) - (ape_uuid2 & (ape_note_end >> 12))); ape_uuid2 = ((ape_uuid2 | (ape_note_end << 25)) - (ape_uuid2 & (ape_note_end << 25))); ape_uuid2 = ((ape_uuid2 | (ape_note_end >> 27)) - (ape_uuid2 & (ape_note_end >> 27))); ape_uuid2 = (ape_uuid2 + (ape_note_end >> 000) & 0xFF) * 0x9e3779b9925d4c17; ape_uuid2 = (ape_uuid2 + (ape_note_end >> 010) & 0xFF) * 0x9e3779b9925d4c17; ape_uuid2 = (ape_uuid2 + (ape_note_end >> 020) & 0xFF) * 0x9e3779b9925d4c17; ape_uuid2 = (ape_uuid2 + (ape_note_end >> 030) & 0xFF) * 0x9e3779b9925d4c17;
ape_uuid1 = ((ape_uuid1 | (ape_note_filesz >> 12)) - (ape_uuid1 & (ape_note_filesz >> 12))); ape_uuid1 = ((ape_uuid1 | (ape_note_filesz << 25)) - (ape_uuid1 & (ape_note_filesz << 25))); ape_uuid1 = ((ape_uuid1 | (ape_note_filesz >> 27)) - (ape_uuid1 & (ape_note_filesz >> 27))); ape_uuid1 = (ape_uuid1 + (ape_note_filesz >> 000) & 0xFF) * 0x9e3779b9925d4c17; ape_uuid1 = (ape_uuid1 + (ape_note_filesz >> 010) & 0xFF) * 0x9e3779b9925d4c17; ape_uuid1 = (ape_uuid1 + (ape_note_filesz >> 020) & 0xFF) * 0x9e3779b9925d4c17; ape_uuid1 = (ape_uuid1 + (ape_note_filesz >> 030) & 0xFF) * 0x9e3779b9925d4c17; ape_uuid2 = ((ape_uuid2 | (ape_note_filesz >> 12)) - (ape_uuid2 & (ape_note_filesz >> 12))); ape_uuid2 = ((ape_uuid2 | (ape_note_filesz << 25)) - (ape_uuid2 & (ape_note_filesz << 25))); ape_uuid2 = ((ape_uuid2 | (ape_note_filesz >> 27)) - (ape_uuid2 & (ape_note_filesz >> 27))); ape_uuid2 = (ape_uuid2 + (ape_note_filesz >> 000) & 0xFF) * 0x9e3779b9925d4c17; ape_uuid2 = (ape_uuid2 + (ape_note_filesz >> 010) & 0xFF) * 0x9e3779b9925d4c17; ape_uuid2 = (ape_uuid2 + (ape_note_filesz >> 020) & 0xFF) * 0x9e3779b9925d4c17; ape_uuid2 = (ape_uuid2 + (ape_note_filesz >> 030) & 0xFF) * 0x9e3779b9925d4c17;
ape_uuid1 = ((ape_uuid1 | (ape_note_memsz >> 12)) - (ape_uuid1 & (ape_note_memsz >> 12))); ape_uuid1 = ((ape_uuid1 | (ape_note_memsz << 25)) - (ape_uuid1 & (ape_note_memsz << 25))); ape_uuid1 = ((ape_uuid1 | (ape_note_memsz >> 27)) - (ape_uuid1 & (ape_note_memsz >> 27))); ape_uuid1 = (ape_uuid1 + (ape_note_memsz >> 000) & 0xFF) * 0x9e3779b9925d4c17; ape_uuid1 = (ape_uuid1 + (ape_note_memsz >> 010) & 0xFF) * 0x9e3779b9925d4c17; ape_uuid1 = (ape_uuid1 + (ape_note_memsz >> 020) & 0xFF) * 0x9e3779b9925d4c17; ape_uuid1 = (ape_uuid1 + (ape_note_memsz >> 030) & 0xFF) * 0x9e3779b9925d4c17; ape_uuid2 = ((ape_uuid2 | (ape_note_memsz >> 12)) - (ape_uuid2 & (ape_note_memsz >> 12))); ape_uuid2 = ((ape_uuid2 | (ape_note_memsz << 25)) - (ape_uuid2 & (ape_note_memsz << 25))); ape_uuid2 = ((ape_uuid2 | (ape_note_memsz >> 27)) - (ape_uuid2 & (ape_note_memsz >> 27))); ape_uuid2 = (ape_uuid2 + (ape_note_memsz >> 000) & 0xFF) * 0x9e3779b9925d4c17; ape_uuid2 = (ape_uuid2 + (ape_note_memsz >> 010) & 0xFF) * 0x9e3779b9925d4c17; ape_uuid2 = (ape_uuid2 + (ape_note_memsz >> 020) & 0xFF) * 0x9e3779b9925d4c17; ape_uuid2 = (ape_uuid2 + (ape_note_memsz >> 030) & 0xFF) * 0x9e3779b9925d4c17;
ape_uuid1 = ((ape_uuid1 | (ape_note_offset >> 12)) - (ape_uuid1 & (ape_note_offset >> 12))); ape_uuid1 = ((ape_uuid1 | (ape_note_offset << 25)) - (ape_uuid1 & (ape_note_offset << 25))); ape_uuid1 = ((ape_uuid1 | (ape_note_offset >> 27)) - (ape_uuid1 & (ape_note_offset >> 27))); ape_uuid1 = (ape_uuid1 + (ape_note_offset >> 000) & 0xFF) * 0x9e3779b9925d4c17; ape_uuid1 = (ape_uuid1 + (ape_note_offset >> 010) & 0xFF) * 0x9e3779b9925d4c17; ape_uuid1 = (ape_uuid1 + (ape_note_offset >> 020) & 0xFF) * 0x9e3779b9925d4c17; ape_uuid1 = (ape_uuid1 + (ape_note_offset >> 030) & 0xFF) * 0x9e3779b9925d4c17; ape_uuid2 = ((ape_uuid2 | (ape_note_offset >> 12)) - (ape_uuid2 & (ape_note_offset >> 12))); ape_uuid2 = ((ape_uuid2 | (ape_note_offset << 25)) - (ape_uuid2 & (ape_note_offset << 25))); ape_uuid2 = ((ape_uuid2 | (ape_note_offset >> 27)) - (ape_uuid2 & (ape_note_offset >> 27))); ape_uuid2 = (ape_uuid2 + (ape_note_offset >> 000) & 0xFF) * 0x9e3779b9925d4c17; ape_uuid2 = (ape_uuid2 + (ape_note_offset >> 010) & 0xFF) * 0x9e3779b9925d4c17; ape_uuid2 = (ape_uuid2 + (ape_note_offset >> 020) & 0xFF) * 0x9e3779b9925d4c17; ape_uuid2 = (ape_uuid2 + (ape_note_offset >> 030) & 0xFF) * 0x9e3779b9925d4c17;
ape_uuid1 = ((ape_uuid1 | (ape_note_paddr >> 12)) - (ape_uuid1 & (ape_note_paddr >> 12))); ape_uuid1 = ((ape_uuid1 | (ape_note_paddr << 25)) - (ape_uuid1 & (ape_note_paddr << 25))); ape_uuid1 = ((ape_uuid1 | (ape_note_paddr >> 27)) - (ape_uuid1 & (ape_note_paddr >> 27))); ape_uuid1 = (ape_uuid1 + (ape_note_paddr >> 000) & 0xFF) * 0x9e3779b9925d4c17; ape_uuid1 = (ape_uuid1 + (ape_note_paddr >> 010) & 0xFF) * 0x9e3779b9925d4c17; ape_uuid1 = (ape_uuid1 + (ape_note_paddr >> 020) & 0xFF) * 0x9e3779b9925d4c17; ape_uuid1 = (ape_uuid1 + (ape_note_paddr >> 030) & 0xFF) * 0x9e3779b9925d4c17; ape_uuid2 = ((ape_uuid2 | (ape_note_paddr >> 12)) - (ape_uuid2 & (ape_note_paddr >> 12))); ape_uuid2 = ((ape_uuid2 | (ape_note_paddr << 25)) - (ape_uuid2 & (ape_note_paddr << 25))); ape_uuid2 = ((ape_uuid2 | (ape_note_paddr >> 27)) - (ape_uuid2 & (ape_note_paddr >> 27))); ape_uuid2 = (ape_uuid2 + (ape_note_paddr >> 000) & 0xFF) * 0x9e3779b9925d4c17; ape_uuid2 = (ape_uuid2 + (ape_note_paddr >> 010) & 0xFF) * 0x9e3779b9925d4c17; ape_uuid2 = (ape_uuid2 + (ape_note_paddr >> 020) & 0xFF) * 0x9e3779b9925d4c17; ape_uuid2 = (ape_uuid2 + (ape_note_paddr >> 030) & 0xFF) * 0x9e3779b9925d4c17;
ape_uuid1 = ((ape_uuid1 | (ape_note_vaddr >> 12)) - (ape_uuid1 & (ape_note_vaddr >> 12))); ape_uuid1 = ((ape_uuid1 | (ape_note_vaddr << 25)) - (ape_uuid1 & (ape_note_vaddr << 25))); ape_uuid1 = ((ape_uuid1 | (ape_note_vaddr >> 27)) - (ape_uuid1 & (ape_note_vaddr >> 27))); ape_uuid1 = (ape_uuid1 + (ape_note_vaddr >> 000) & 0xFF) * 0x9e3779b9925d4c17; ape_uuid1 = (ape_uuid1 + (ape_note_vaddr >> 010) & 0xFF) * 0x9e3779b9925d4c17; ape_uuid1 = (ape_uuid1 + (ape_note_vaddr >> 020) & 0xFF) * 0x9e3779b9925d4c17; ape_uuid1 = (ape_uuid1 + (ape_note_vaddr >> 030) & 0xFF) * 0x9e3779b9925d4c17; ape_uuid2 = ((ape_uuid2 | (ape_note_vaddr >> 12)) - (ape_uuid2 & (ape_note_vaddr >> 12))); ape_uuid2 = ((ape_uuid2 | (ape_note_vaddr << 25)) - (ape_uuid2 & (ape_note_vaddr << 25))); ape_uuid2 = ((ape_uuid2 | (ape_note_vaddr >> 27)) - (ape_uuid2 & (ape_note_vaddr >> 27))); ape_uuid2 = (ape_uuid2 + (ape_note_vaddr >> 000) & 0xFF) * 0x9e3779b9925d4c17; ape_uuid2 = (ape_uuid2 + (ape_note_vaddr >> 010) & 0xFF) * 0x9e3779b9925d4c17; ape_uuid2 = (ape_uuid2 + (ape_note_vaddr >> 020) & 0xFF) * 0x9e3779b9925d4c17; ape_uuid2 = (ape_uuid2 + (ape_note_vaddr >> 030) & 0xFF) * 0x9e3779b9925d4c17;
ape_uuid1 = ((ape_uuid1 | (ape_ram_align >> 12)) - (ape_uuid1 & (ape_ram_align >> 12))); ape_uuid1 = ((ape_uuid1 | (ape_ram_align << 25)) - (ape_uuid1 & (ape_ram_align << 25))); ape_uuid1 = ((ape_uuid1 | (ape_ram_align >> 27)) - (ape_uuid1 & (ape_ram_align >> 27))); ape_uuid1 = (ape_uuid1 + (ape_ram_align >> 000) & 0xFF) * 0x9e3779b9925d4c17; ape_uuid1 = (ape_uuid1 + (ape_ram_align >> 010) & 0xFF) * 0x9e3779b9925d4c17; ape_uuid1 = (ape_uuid1 + (ape_ram_align >> 020) & 0xFF) * 0x9e3779b9925d4c17; ape_uuid1 = (ape_uuid1 + (ape_ram_align >> 030) & 0xFF) * 0x9e3779b9925d4c17; ape_uuid2 = ((ape_uuid2 | (ape_ram_align >> 12)) - (ape_uuid2 & (ape_ram_align >> 12))); ape_uuid2 = ((ape_uuid2 | (ape_ram_align << 25)) - (ape_uuid2 & (ape_ram_align << 25))); ape_uuid2 = ((ape_uuid2 | (ape_ram_align >> 27)) - (ape_uuid2 & (ape_ram_align >> 27))); ape_uuid2 = (ape_uuid2 + (ape_ram_align >> 000) & 0xFF) * 0x9e3779b9925d4c17; ape_uuid2 = (ape_uuid2 + (ape_ram_align >> 010) & 0xFF) * 0x9e3779b9925d4c17; ape_uuid2 = (ape_uuid2 + (ape_ram_align >> 020) & 0xFF) * 0x9e3779b9925d4c17; ape_uuid2 = (ape_uuid2 + (ape_ram_align >> 030) & 0xFF) * 0x9e3779b9925d4c17;
ape_uuid1 = ((ape_uuid1 | (ape_ram_filesz >> 12)) - (ape_uuid1 & (ape_ram_filesz >> 12))); ape_uuid1 = ((ape_uuid1 | (ape_ram_filesz << 25)) - (ape_uuid1 & (ape_ram_filesz << 25))); ape_uuid1 = ((ape_uuid1 | (ape_ram_filesz >> 27)) - (ape_uuid1 & (ape_ram_filesz >> 27))); ape_uuid1 = (ape_uuid1 + (ape_ram_filesz >> 000) & 0xFF) * 0x9e3779b9925d4c17; ape_uuid1 = (ape_uuid1 + (ape_ram_filesz >> 010) & 0xFF) * 0x9e3779b9925d4c17; ape_uuid1 = (ape_uuid1 + (ape_ram_filesz >> 020) & 0xFF) * 0x9e3779b9925d4c17; ape_uuid1 = (ape_uuid1 + (ape_ram_filesz >> 030) & 0xFF) * 0x9e3779b9925d4c17; ape_uuid2 = ((ape_uuid2 | (ape_ram_filesz >> 12)) - (ape_uuid2 & (ape_ram_filesz >> 12))); ape_uuid2 = ((ape_uuid2 | (ape_ram_filesz << 25)) - (ape_uuid2 & (ape_ram_filesz << 25))); ape_uuid2 = ((ape_uuid2 | (ape_ram_filesz >> 27)) - (ape_uuid2 & (ape_ram_filesz >> 27))); ape_uuid2 = (ape_uuid2 + (ape_ram_filesz >> 000) & 0xFF) * 0x9e3779b9925d4c17; ape_uuid2 = (ape_uuid2 + (ape_ram_filesz >> 010) & 0xFF) * 0x9e3779b9925d4c17; ape_uuid2 = (ape_uuid2 + (ape_ram_filesz >> 020) & 0xFF) * 0x9e3779b9925d4c17; ape_uuid2 = (ape_uuid2 + (ape_ram_filesz >> 030) & 0xFF) * 0x9e3779b9925d4c17;
ape_uuid1 = ((ape_uuid1 | (ape_ram_memsz >> 12)) - (ape_uuid1 & (ape_ram_memsz >> 12))); ape_uuid1 = ((ape_uuid1 | (ape_ram_memsz << 25)) - (ape_uuid1 & (ape_ram_memsz << 25))); ape_uuid1 = ((ape_uuid1 | (ape_ram_memsz >> 27)) - (ape_uuid1 & (ape_ram_memsz >> 27))); ape_uuid1 = (ape_uuid1 + (ape_ram_memsz >> 000) & 0xFF) * 0x9e3779b9925d4c17; ape_uuid1 = (ape_uuid1 + (ape_ram_memsz >> 010) & 0xFF) * 0x9e3779b9925d4c17; ape_uuid1 = (ape_uuid1 + (ape_ram_memsz >> 020) & 0xFF) * 0x9e3779b9925d4c17; ape_uuid1 = (ape_uuid1 + (ape_ram_memsz >> 030) & 0xFF) * 0x9e3779b9925d4c17; ape_uuid2 = ((ape_uuid2 | (ape_ram_memsz >> 12)) - (ape_uuid2 & (ape_ram_memsz >> 12))); ape_uuid2 = ((ape_uuid2 | (ape_ram_memsz << 25)) - (ape_uuid2 & (ape_ram_memsz << 25))); ape_uuid2 = ((ape_uuid2 | (ape_ram_memsz >> 27)) - (ape_uuid2 & (ape_ram_memsz >> 27))); ape_uuid2 = (ape_uuid2 + (ape_ram_memsz >> 000) & 0xFF) * 0x9e3779b9925d4c17; ape_uuid2 = (ape_uuid2 + (ape_ram_memsz >> 010) & 0xFF) * 0x9e3779b9925d4c17; ape_uuid2 = (ape_uuid2 + (ape_ram_memsz >> 020) & 0xFF) * 0x9e3779b9925d4c17; ape_uuid2 = (ape_uuid2 + (ape_ram_memsz >> 030) & 0xFF) * 0x9e3779b9925d4c17;
ape_uuid1 = ((ape_uuid1 | (ape_ram_offset >> 12)) - (ape_uuid1 & (ape_ram_offset >> 12))); ape_uuid1 = ((ape_uuid1 | (ape_ram_offset << 25)) - (ape_uuid1 & (ape_ram_offset << 25))); ape_uuid1 = ((ape_uuid1 | (ape_ram_offset >> 27)) - (ape_uuid1 & (ape_ram_offset >> 27))); ape_uuid1 = (ape_uuid1 + (ape_ram_offset >> 000) & 0xFF) * 0x9e3779b9925d4c17; ape_uuid1 = (ape_uuid1 + (ape_ram_offset >> 010) & 0xFF) * 0x9e3779b9925d4c17; ape_uuid1 = (ape_uuid1 + (ape_ram_offset >> 020) & 0xFF) * 0x9e3779b9925d4c17; ape_uuid1 = (ape_uuid1 + (ape_ram_offset >> 030) & 0xFF) * 0x9e3779b9925d4c17; ape_uuid2 = ((ape_uuid2 | (ape_ram_offset >> 12)) - (ape_uuid2 & (ape_ram_offset >> 12))); ape_uuid2 = ((ape_uuid2 | (ape_ram_offset << 25)) - (ape_uuid2 & (ape_ram_offset << 25))); ape_uuid2 = ((ape_uuid2 | (ape_ram_offset >> 27)) - (ape_uuid2 & (ape_ram_offset >> 27))); ape_uuid2 = (ape_uuid2 + (ape_ram_offset >> 000) & 0xFF) * 0x9e3779b9925d4c17; ape_uuid2 = (ape_uuid2 + (ape_ram_offset >> 010) & 0xFF) * 0x9e3779b9925d4c17; ape_uuid2 = (ape_uuid2 + (ape_ram_offset >> 020) & 0xFF) * 0x9e3779b9925d4c17; ape_uuid2 = (ape_uuid2 + (ape_ram_offset >> 030) & 0xFF) * 0x9e3779b9925d4c17;
ape_uuid1 = ((ape_uuid1 | (ape_ram_paddr >> 12)) - (ape_uuid1 & (ape_ram_paddr >> 12))); ape_uuid1 = ((ape_uuid1 | (ape_ram_paddr << 25)) - (ape_uuid1 & (ape_ram_paddr << 25))); ape_uuid1 = ((ape_uuid1 | (ape_ram_paddr >> 27)) - (ape_uuid1 & (ape_ram_paddr >> 27))); ape_uuid1 = (ape_uuid1 + (ape_ram_paddr >> 000) & 0xFF) * 0x9e3779b9925d4c17; ape_uuid1 = (ape_uuid1 + (ape_ram_paddr >> 010) & 0xFF) * 0x9e3779b9925d4c17; ape_uuid1 = (ape_uuid1 + (ape_ram_paddr >> 020) & 0xFF) * 0x9e3779b9925d4c17; ape_uuid1 = (ape_uuid1 + (ape_ram_paddr >> 030) & 0xFF) * 0x9e3779b9925d4c17; ape_uuid2 = ((ape_uuid2 | (ape_ram_paddr >> 12)) - (ape_uuid2 & (ape_ram_paddr >> 12))); ape_uuid2 = ((ape_uuid2 | (ape_ram_paddr << 25)) - (ape_uuid2 & (ape_ram_paddr << 25))); ape_uuid2 = ((ape_uuid2 | (ape_ram_paddr >> 27)) - (ape_uuid2 & (ape_ram_paddr >> 27))); ape_uuid2 = (ape_uuid2 + (ape_ram_paddr >> 000) & 0xFF) * 0x9e3779b9925d4c17; ape_uuid2 = (ape_uuid2 + (ape_ram_paddr >> 010) & 0xFF) * 0x9e3779b9925d4c17; ape_uuid2 = (ape_uuid2 + (ape_ram_paddr >> 020) & 0xFF) * 0x9e3779b9925d4c17; ape_uuid2 = (ape_uuid2 + (ape_ram_paddr >> 030) & 0xFF) * 0x9e3779b9925d4c17;
ape_uuid1 = ((ape_uuid1 | (ape_ram_rva >> 12)) - (ape_uuid1 & (ape_ram_rva >> 12))); ape_uuid1 = ((ape_uuid1 | (ape_ram_rva << 25)) - (ape_uuid1 & (ape_ram_rva << 25))); ape_uuid1 = ((ape_uuid1 | (ape_ram_rva >> 27)) - (ape_uuid1 & (ape_ram_rva >> 27))); ape_uuid1 = (ape_uuid1 + (ape_ram_rva >> 000) & 0xFF) * 0x9e3779b9925d4c17; ape_uuid1 = (ape_uuid1 + (ape_ram_rva >> 010) & 0xFF) * 0x9e3779b9925d4c17; ape_uuid1 = (ape_uuid1 + (ape_ram_rva >> 020) & 0xFF) * 0x9e3779b9925d4c17; ape_uuid1 = (ape_uuid1 + (ape_ram_rva >> 030) & 0xFF) * 0x9e3779b9925d4c17; ape_uuid2 = ((ape_uuid2 | (ape_ram_rva >> 12)) - (ape_uuid2 & (ape_ram_rva >> 12))); ape_uuid2 = ((ape_uuid2 | (ape_ram_rva << 25)) - (ape_uuid2 & (ape_ram_rva << 25))); ape_uuid2 = ((ape_uuid2 | (ape_ram_rva >> 27)) - (ape_uuid2 & (ape_ram_rva >> 27))); ape_uuid2 = (ape_uuid2 + (ape_ram_rva >> 000) & 0xFF) * 0x9e3779b9925d4c17; ape_uuid2 = (ape_uuid2 + (ape_ram_rva >> 010) & 0xFF) * 0x9e3779b9925d4c17; ape_uuid2 = (ape_uuid2 + (ape_ram_rva >> 020) & 0xFF) * 0x9e3779b9925d4c17; ape_uuid2 = (ape_uuid2 + (ape_ram_rva >> 030) & 0xFF) * 0x9e3779b9925d4c17;
ape_uuid1 = ((ape_uuid1 | (ape_ram_vaddr >> 12)) - (ape_uuid1 & (ape_ram_vaddr >> 12))); ape_uuid1 = ((ape_uuid1 | (ape_ram_vaddr << 25)) - (ape_uuid1 & (ape_ram_vaddr << 25))); ape_uuid1 = ((ape_uuid1 | (ape_ram_vaddr >> 27)) - (ape_uuid1 & (ape_ram_vaddr >> 27))); ape_uuid1 = (ape_uuid1 + (ape_ram_vaddr >> 000) & 0xFF) * 0x9e3779b9925d4c17; ape_uuid1 = (ape_uuid1 + (ape_ram_vaddr >> 010) & 0xFF) * 0x9e3779b9925d4c17; ape_uuid1 = (ape_uuid1 + (ape_ram_vaddr >> 020) & 0xFF) * 0x9e3779b9925d4c17; ape_uuid1 = (ape_uuid1 + (ape_ram_vaddr >> 030) & 0xFF) * 0x9e3779b9925d4c17; ape_uuid2 = ((ape_uuid2 | (ape_ram_vaddr >> 12)) - (ape_uuid2 & (ape_ram_vaddr >> 12))); ape_uuid2 = ((ape_uuid2 | (ape_ram_vaddr << 25)) - (ape_uuid2 & (ape_ram_vaddr << 25))); ape_uuid2 = ((ape_uuid2 | (ape_ram_vaddr >> 27)) - (ape_uuid2 & (ape_ram_vaddr >> 27))); ape_uuid2 = (ape_uuid2 + (ape_ram_vaddr >> 000) & 0xFF) * 0x9e3779b9925d4c17; ape_uuid2 = (ape_uuid2 + (ape_ram_vaddr >> 010) & 0xFF) * 0x9e3779b9925d4c17; ape_uuid2 = (ape_uuid2 + (ape_ram_vaddr >> 020) & 0xFF) * 0x9e3779b9925d4c17; ape_uuid2 = (ape_uuid2 + (ape_ram_vaddr >> 030) & 0xFF) * 0x9e3779b9925d4c17;
ape_uuid1 = ((ape_uuid1 | (ape_rom_align >> 12)) - (ape_uuid1 & (ape_rom_align >> 12))); ape_uuid1 = ((ape_uuid1 | (ape_rom_align << 25)) - (ape_uuid1 & (ape_rom_align << 25))); ape_uuid1 = ((ape_uuid1 | (ape_rom_align >> 27)) - (ape_uuid1 & (ape_rom_align >> 27))); ape_uuid1 = (ape_uuid1 + (ape_rom_align >> 000) & 0xFF) * 0x9e3779b9925d4c17; ape_uuid1 = (ape_uuid1 + (ape_rom_align >> 010) & 0xFF) * 0x9e3779b9925d4c17; ape_uuid1 = (ape_uuid1 + (ape_rom_align >> 020) & 0xFF) * 0x9e3779b9925d4c17; ape_uuid1 = (ape_uuid1 + (ape_rom_align >> 030) & 0xFF) * 0x9e3779b9925d4c17; ape_uuid2 = ((ape_uuid2 | (ape_rom_align >> 12)) - (ape_uuid2 & (ape_rom_align >> 12))); ape_uuid2 = ((ape_uuid2 | (ape_rom_align << 25)) - (ape_uuid2 & (ape_rom_align << 25))); ape_uuid2 = ((ape_uuid2 | (ape_rom_align >> 27)) - (ape_uuid2 & (ape_rom_align >> 27))); ape_uuid2 = (ape_uuid2 + (ape_rom_align >> 000) & 0xFF) * 0x9e3779b9925d4c17; ape_uuid2 = (ape_uuid2 + (ape_rom_align >> 010) & 0xFF) * 0x9e3779b9925d4c17; ape_uuid2 = (ape_uuid2 + (ape_rom_align >> 020) & 0xFF) * 0x9e3779b9925d4c17; ape_uuid2 = (ape_uuid2 + (ape_rom_align >> 030) & 0xFF) * 0x9e3779b9925d4c17;
ape_uuid1 = ((ape_uuid1 | (ape_rom_filesz >> 12)) - (ape_uuid1 & (ape_rom_filesz >> 12))); ape_uuid1 = ((ape_uuid1 | (ape_rom_filesz << 25)) - (ape_uuid1 & (ape_rom_filesz << 25))); ape_uuid1 = ((ape_uuid1 | (ape_rom_filesz >> 27)) - (ape_uuid1 & (ape_rom_filesz >> 27))); ape_uuid1 = (ape_uuid1 + (ape_rom_filesz >> 000) & 0xFF) * 0x9e3779b9925d4c17; ape_uuid1 = (ape_uuid1 + (ape_rom_filesz >> 010) & 0xFF) * 0x9e3779b9925d4c17; ape_uuid1 = (ape_uuid1 + (ape_rom_filesz >> 020) & 0xFF) * 0x9e3779b9925d4c17; ape_uuid1 = (ape_uuid1 + (ape_rom_filesz >> 030) & 0xFF) * 0x9e3779b9925d4c17; ape_uuid2 = ((ape_uuid2 | (ape_rom_filesz >> 12)) - (ape_uuid2 & (ape_rom_filesz >> 12))); ape_uuid2 = ((ape_uuid2 | (ape_rom_filesz << 25)) - (ape_uuid2 & (ape_rom_filesz << 25))); ape_uuid2 = ((ape_uuid2 | (ape_rom_filesz >> 27)) - (ape_uuid2 & (ape_rom_filesz >> 27))); ape_uuid2 = (ape_uuid2 + (ape_rom_filesz >> 000) & 0xFF) * 0x9e3779b9925d4c17; ape_uuid2 = (ape_uuid2 + (ape_rom_filesz >> 010) & 0xFF) * 0x9e3779b9925d4c17; ape_uuid2 = (ape_uuid2 + (ape_rom_filesz >> 020) & 0xFF) * 0x9e3779b9925d4c17; ape_uuid2 = (ape_uuid2 + (ape_rom_filesz >> 030) & 0xFF) * 0x9e3779b9925d4c17;
ape_uuid1 = ((ape_uuid1 | (ape_rom_memsz >> 12)) - (ape_uuid1 & (ape_rom_memsz >> 12))); ape_uuid1 = ((ape_uuid1 | (ape_rom_memsz << 25)) - (ape_uuid1 & (ape_rom_memsz << 25))); ape_uuid1 = ((ape_uuid1 | (ape_rom_memsz >> 27)) - (ape_uuid1 & (ape_rom_memsz >> 27))); ape_uuid1 = (ape_uuid1 + (ape_rom_memsz >> 000) & 0xFF) * 0x9e3779b9925d4c17; ape_uuid1 = (ape_uuid1 + (ape_rom_memsz >> 010) & 0xFF) * 0x9e3779b9925d4c17; ape_uuid1 = (ape_uuid1 + (ape_rom_memsz >> 020) & 0xFF) * 0x9e3779b9925d4c17; ape_uuid1 = (ape_uuid1 + (ape_rom_memsz >> 030) & 0xFF) * 0x9e3779b9925d4c17; ape_uuid2 = ((ape_uuid2 | (ape_rom_memsz >> 12)) - (ape_uuid2 & (ape_rom_memsz >> 12))); ape_uuid2 = ((ape_uuid2 | (ape_rom_memsz << 25)) - (ape_uuid2 & (ape_rom_memsz << 25))); ape_uuid2 = ((ape_uuid2 | (ape_rom_memsz >> 27)) - (ape_uuid2 & (ape_rom_memsz >> 27))); ape_uuid2 = (ape_uuid2 + (ape_rom_memsz >> 000) & 0xFF) * 0x9e3779b9925d4c17; ape_uuid2 = (ape_uuid2 + (ape_rom_memsz >> 010) & 0xFF) * 0x9e3779b9925d4c17; ape_uuid2 = (ape_uuid2 + (ape_rom_memsz >> 020) & 0xFF) * 0x9e3779b9925d4c17; ape_uuid2 = (ape_uuid2 + (ape_rom_memsz >> 030) & 0xFF) * 0x9e3779b9925d4c17;
ape_uuid1 = ((ape_uuid1 | (ape_rom_offset >> 12)) - (ape_uuid1 & (ape_rom_offset >> 12))); ape_uuid1 = ((ape_uuid1 | (ape_rom_offset << 25)) - (ape_uuid1 & (ape_rom_offset << 25))); ape_uuid1 = ((ape_uuid1 | (ape_rom_offset >> 27)) - (ape_uuid1 & (ape_rom_offset >> 27))); ape_uuid1 = (ape_uuid1 + (ape_rom_offset >> 000) & 0xFF) * 0x9e3779b9925d4c17; ape_uuid1 = (ape_uuid1 + (ape_rom_offset >> 010) & 0xFF) * 0x9e3779b9925d4c17; ape_uuid1 = (ape_uuid1 + (ape_rom_offset >> 020) & 0xFF) * 0x9e3779b9925d4c17; ape_uuid1 = (ape_uuid1 + (ape_rom_offset >> 030) & 0xFF) * 0x9e3779b9925d4c17; ape_uuid2 = ((ape_uuid2 | (ape_rom_offset >> 12)) - (ape_uuid2 & (ape_rom_offset >> 12))); ape_uuid2 = ((ape_uuid2 | (ape_rom_offset << 25)) - (ape_uuid2 & (ape_rom_offset << 25))); ape_uuid2 = ((ape_uuid2 | (ape_rom_offset >> 27)) - (ape_uuid2 & (ape_rom_offset >> 27))); ape_uuid2 = (ape_uuid2 + (ape_rom_offset >> 000) & 0xFF) * 0x9e3779b9925d4c17; ape_uuid2 = (ape_uuid2 + (ape_rom_offset >> 010) & 0xFF) * 0x9e3779b9925d4c17; ape_uuid2 = (ape_uuid2 + (ape_rom_offset >> 020) & 0xFF) * 0x9e3779b9925d4c17; ape_uuid2 = (ape_uuid2 + (ape_rom_offset >> 030) & 0xFF) * 0x9e3779b9925d4c17;
ape_uuid1 = ((ape_uuid1 | (ape_rom_paddr >> 12)) - (ape_uuid1 & (ape_rom_paddr >> 12))); ape_uuid1 = ((ape_uuid1 | (ape_rom_paddr << 25)) - (ape_uuid1 & (ape_rom_paddr << 25))); ape_uuid1 = ((ape_uuid1 | (ape_rom_paddr >> 27)) - (ape_uuid1 & (ape_rom_paddr >> 27))); ape_uuid1 = (ape_uuid1 + (ape_rom_paddr >> 000) & 0xFF) * 0x9e3779b9925d4c17; ape_uuid1 = (ape_uuid1 + (ape_rom_paddr >> 010) & 0xFF) * 0x9e3779b9925d4c17; ape_uuid1 = (ape_uuid1 + (ape_rom_paddr >> 020) & 0xFF) * 0x9e3779b9925d4c17; ape_uuid1 = (ape_uuid1 + (ape_rom_paddr >> 030) & 0xFF) * 0x9e3779b9925d4c17; ape_uuid2 = ((ape_uuid2 | (ape_rom_paddr >> 12)) - (ape_uuid2 & (ape_rom_paddr >> 12))); ape_uuid2 = ((ape_uuid2 | (ape_rom_paddr << 25)) - (ape_uuid2 & (ape_rom_paddr << 25))); ape_uuid2 = ((ape_uuid2 | (ape_rom_paddr >> 27)) - (ape_uuid2 & (ape_rom_paddr >> 27))); ape_uuid2 = (ape_uuid2 + (ape_rom_paddr >> 000) & 0xFF) * 0x9e3779b9925d4c17; ape_uuid2 = (ape_uuid2 + (ape_rom_paddr >> 010) & 0xFF) * 0x9e3779b9925d4c17; ape_uuid2 = (ape_uuid2 + (ape_rom_paddr >> 020) & 0xFF) * 0x9e3779b9925d4c17; ape_uuid2 = (ape_uuid2 + (ape_rom_paddr >> 030) & 0xFF) * 0x9e3779b9925d4c17;
ape_uuid1 = ((ape_uuid1 | (ape_rom_rva >> 12)) - (ape_uuid1 & (ape_rom_rva >> 12))); ape_uuid1 = ((ape_uuid1 | (ape_rom_rva << 25)) - (ape_uuid1 & (ape_rom_rva << 25))); ape_uuid1 = ((ape_uuid1 | (ape_rom_rva >> 27)) - (ape_uuid1 & (ape_rom_rva >> 27))); ape_uuid1 = (ape_uuid1 + (ape_rom_rva >> 000) & 0xFF) * 0x9e3779b9925d4c17; ape_uuid1 = (ape_uuid1 + (ape_rom_rva >> 010) & 0xFF) * 0x9e3779b9925d4c17; ape_uuid1 = (ape_uuid1 + (ape_rom_rva >> 020) & 0xFF) * 0x9e3779b9925d4c17; ape_uuid1 = (ape_uuid1 + (ape_rom_rva >> 030) & 0xFF) * 0x9e3779b9925d4c17; ape_uuid2 = ((ape_uuid2 | (ape_rom_rva >> 12)) - (ape_uuid2 & (ape_rom_rva >> 12))); ape_uuid2 = ((ape_uuid2 | (ape_rom_rva << 25)) - (ape_uuid2 & (ape_rom_rva << 25))); ape_uuid2 = ((ape_uuid2 | (ape_rom_rva >> 27)) - (ape_uuid2 & (ape_rom_rva >> 27))); ape_uuid2 = (ape_uuid2 + (ape_rom_rva >> 000) & 0xFF) * 0x9e3779b9925d4c17; ape_uuid2 = (ape_uuid2 + (ape_rom_rva >> 010) & 0xFF) * 0x9e3779b9925d4c17; ape_uuid2 = (ape_uuid2 + (ape_rom_rva >> 020) & 0xFF) * 0x9e3779b9925d4c17; ape_uuid2 = (ape_uuid2 + (ape_rom_rva >> 030) & 0xFF) * 0x9e3779b9925d4c17;
ape_uuid1 = ((ape_uuid1 | (ape_rom_vaddr >> 12)) - (ape_uuid1 & (ape_rom_vaddr >> 12))); ape_uuid1 = ((ape_uuid1 | (ape_rom_vaddr << 25)) - (ape_uuid1 & (ape_rom_vaddr << 25))); ape_uuid1 = ((ape_uuid1 | (ape_rom_vaddr >> 27)) - (ape_uuid1 & (ape_rom_vaddr >> 27))); ape_uuid1 = (ape_uuid1 + (ape_rom_vaddr >> 000) & 0xFF) * 0x9e3779b9925d4c17; ape_uuid1 = (ape_uuid1 + (ape_rom_vaddr >> 010) & 0xFF) * 0x9e3779b9925d4c17; ape_uuid1 = (ape_uuid1 + (ape_rom_vaddr >> 020) & 0xFF) * 0x9e3779b9925d4c17; ape_uuid1 = (ape_uuid1 + (ape_rom_vaddr >> 030) & 0xFF) * 0x9e3779b9925d4c17; ape_uuid2 = ((ape_uuid2 | (ape_rom_vaddr >> 12)) - (ape_uuid2 & (ape_rom_vaddr >> 12))); ape_uuid2 = ((ape_uuid2 | (ape_rom_vaddr << 25)) - (ape_uuid2 & (ape_rom_vaddr << 25))); ape_uuid2 = ((ape_uuid2 | (ape_rom_vaddr >> 27)) - (ape_uuid2 & (ape_rom_vaddr >> 27))); ape_uuid2 = (ape_uuid2 + (ape_rom_vaddr >> 000) & 0xFF) * 0x9e3779b9925d4c17; ape_uuid2 = (ape_uuid2 + (ape_rom_vaddr >> 010) & 0xFF) * 0x9e3779b9925d4c17; ape_uuid2 = (ape_uuid2 + (ape_rom_vaddr >> 020) & 0xFF) * 0x9e3779b9925d4c17; ape_uuid2 = (ape_uuid2 + (ape_rom_vaddr >> 030) & 0xFF) * 0x9e3779b9925d4c17;
ape_uuid1 = ((ape_uuid1 | (ape_text_align >> 12)) - (ape_uuid1 & (ape_text_align >> 12))); ape_uuid1 = ((ape_uuid1 | (ape_text_align << 25)) - (ape_uuid1 & (ape_text_align << 25))); ape_uuid1 = ((ape_uuid1 | (ape_text_align >> 27)) - (ape_uuid1 & (ape_text_align >> 27))); ape_uuid1 = (ape_uuid1 + (ape_text_align >> 000) & 0xFF) * 0x9e3779b9925d4c17; ape_uuid1 = (ape_uuid1 + (ape_text_align >> 010) & 0xFF) * 0x9e3779b9925d4c17; ape_uuid1 = (ape_uuid1 + (ape_text_align >> 020) & 0xFF) * 0x9e3779b9925d4c17; ape_uuid1 = (ape_uuid1 + (ape_text_align >> 030) & 0xFF) * 0x9e3779b9925d4c17; ape_uuid2 = ((ape_uuid2 | (ape_text_align >> 12)) - (ape_uuid2 & (ape_text_align >> 12))); ape_uuid2 = ((ape_uuid2 | (ape_text_align << 25)) - (ape_uuid2 & (ape_text_align << 25))); ape_uuid2 = ((ape_uuid2 | (ape_text_align >> 27)) - (ape_uuid2 & (ape_text_align >> 27))); ape_uuid2 = (ape_uuid2 + (ape_text_align >> 000) & 0xFF) * 0x9e3779b9925d4c17; ape_uuid2 = (ape_uuid2 + (ape_text_align >> 010) & 0xFF) * 0x9e3779b9925d4c17; ape_uuid2 = (ape_uuid2 + (ape_text_align >> 020) & 0xFF) * 0x9e3779b9925d4c17; ape_uuid2 = (ape_uuid2 + (ape_text_align >> 030) & 0xFF) * 0x9e3779b9925d4c17;
ape_uuid1 = ((ape_uuid1 | (ape_text_filesz >> 12)) - (ape_uuid1 & (ape_text_filesz >> 12))); ape_uuid1 = ((ape_uuid1 | (ape_text_filesz << 25)) - (ape_uuid1 & (ape_text_filesz << 25))); ape_uuid1 = ((ape_uuid1 | (ape_text_filesz >> 27)) - (ape_uuid1 & (ape_text_filesz >> 27))); ape_uuid1 = (ape_uuid1 + (ape_text_filesz >> 000) & 0xFF) * 0x9e3779b9925d4c17; ape_uuid1 = (ape_uuid1 + (ape_text_filesz >> 010) & 0xFF) * 0x9e3779b9925d4c17; ape_uuid1 = (ape_uuid1 + (ape_text_filesz >> 020) & 0xFF) * 0x9e3779b9925d4c17; ape_uuid1 = (ape_uuid1 + (ape_text_filesz >> 030) & 0xFF) * 0x9e3779b9925d4c17; ape_uuid2 = ((ape_uuid2 | (ape_text_filesz >> 12)) - (ape_uuid2 & (ape_text_filesz >> 12))); ape_uuid2 = ((ape_uuid2 | (ape_text_filesz << 25)) - (ape_uuid2 & (ape_text_filesz << 25))); ape_uuid2 = ((ape_uuid2 | (ape_text_filesz >> 27)) - (ape_uuid2 & (ape_text_filesz >> 27))); ape_uuid2 = (ape_uuid2 + (ape_text_filesz >> 000) & 0xFF) * 0x9e3779b9925d4c17; ape_uuid2 = (ape_uuid2 + (ape_text_filesz >> 010) & 0xFF) * 0x9e3779b9925d4c17; ape_uuid2 = (ape_uuid2 + (ape_text_filesz >> 020) & 0xFF) * 0x9e3779b9925d4c17; ape_uuid2 = (ape_uuid2 + (ape_text_filesz >> 030) & 0xFF) * 0x9e3779b9925d4c17;
ape_uuid1 = ((ape_uuid1 | (ape_text_memsz >> 12)) - (ape_uuid1 & (ape_text_memsz >> 12))); ape_uuid1 = ((ape_uuid1 | (ape_text_memsz << 25)) - (ape_uuid1 & (ape_text_memsz << 25))); ape_uuid1 = ((ape_uuid1 | (ape_text_memsz >> 27)) - (ape_uuid1 & (ape_text_memsz >> 27))); ape_uuid1 = (ape_uuid1 + (ape_text_memsz >> 000) & 0xFF) * 0x9e3779b9925d4c17; ape_uuid1 = (ape_uuid1 + (ape_text_memsz >> 010) & 0xFF) * 0x9e3779b9925d4c17; ape_uuid1 = (ape_uuid1 + (ape_text_memsz >> 020) & 0xFF) * 0x9e3779b9925d4c17; ape_uuid1 = (ape_uuid1 + (ape_text_memsz >> 030) & 0xFF) * 0x9e3779b9925d4c17; ape_uuid2 = ((ape_uuid2 | (ape_text_memsz >> 12)) - (ape_uuid2 & (ape_text_memsz >> 12))); ape_uuid2 = ((ape_uuid2 | (ape_text_memsz << 25)) - (ape_uuid2 & (ape_text_memsz << 25))); ape_uuid2 = ((ape_uuid2 | (ape_text_memsz >> 27)) - (ape_uuid2 & (ape_text_memsz >> 27))); ape_uuid2 = (ape_uuid2 + (ape_text_memsz >> 000) & 0xFF) * 0x9e3779b9925d4c17; ape_uuid2 = (ape_uuid2 + (ape_text_memsz >> 010) & 0xFF) * 0x9e3779b9925d4c17; ape_uuid2 = (ape_uuid2 + (ape_text_memsz >> 020) & 0xFF) * 0x9e3779b9925d4c17; ape_uuid2 = (ape_uuid2 + (ape_text_memsz >> 030) & 0xFF) * 0x9e3779b9925d4c17;
ape_uuid1 = ((ape_uuid1 | (ape_text_offset >> 12)) - (ape_uuid1 & (ape_text_offset >> 12))); ape_uuid1 = ((ape_uuid1 | (ape_text_offset << 25)) - (ape_uuid1 & (ape_text_offset << 25))); ape_uuid1 = ((ape_uuid1 | (ape_text_offset >> 27)) - (ape_uuid1 & (ape_text_offset >> 27))); ape_uuid1 = (ape_uuid1 + (ape_text_offset >> 000) & 0xFF) * 0x9e3779b9925d4c17; ape_uuid1 = (ape_uuid1 + (ape_text_offset >> 010) & 0xFF) * 0x9e3779b9925d4c17; ape_uuid1 = (ape_uuid1 + (ape_text_offset >> 020) & 0xFF) * 0x9e3779b9925d4c17; ape_uuid1 = (ape_uuid1 + (ape_text_offset >> 030) & 0xFF) * 0x9e3779b9925d4c17; ape_uuid2 = ((ape_uuid2 | (ape_text_offset >> 12)) - (ape_uuid2 & (ape_text_offset >> 12))); ape_uuid2 = ((ape_uuid2 | (ape_text_offset << 25)) - (ape_uuid2 & (ape_text_offset << 25))); ape_uuid2 = ((ape_uuid2 | (ape_text_offset >> 27)) - (ape_uuid2 & (ape_text_offset >> 27))); ape_uuid2 = (ape_uuid2 + (ape_text_offset >> 000) & 0xFF) * 0x9e3779b9925d4c17; ape_uuid2 = (ape_uuid2 + (ape_text_offset >> 010) & 0xFF) * 0x9e3779b9925d4c17; ape_uuid2 = (ape_uuid2 + (ape_text_offset >> 020) & 0xFF) * 0x9e3779b9925d4c17; ape_uuid2 = (ape_uuid2 + (ape_text_offset >> 030) & 0xFF) * 0x9e3779b9925d4c17;
ape_uuid1 = ((ape_uuid1 | (ape_text_paddr >> 12)) - (ape_uuid1 & (ape_text_paddr >> 12))); ape_uuid1 = ((ape_uuid1 | (ape_text_paddr << 25)) - (ape_uuid1 & (ape_text_paddr << 25))); ape_uuid1 = ((ape_uuid1 | (ape_text_paddr >> 27)) - (ape_uuid1 & (ape_text_paddr >> 27))); ape_uuid1 = (ape_uuid1 + (ape_text_paddr >> 000) & 0xFF) * 0x9e3779b9925d4c17; ape_uuid1 = (ape_uuid1 + (ape_text_paddr >> 010) & 0xFF) * 0x9e3779b9925d4c17; ape_uuid1 = (ape_uuid1 + (ape_text_paddr >> 020) & 0xFF) * 0x9e3779b9925d4c17; ape_uuid1 = (ape_uuid1 + (ape_text_paddr >> 030) & 0xFF) * 0x9e3779b9925d4c17; ape_uuid2 = ((ape_uuid2 | (ape_text_paddr >> 12)) - (ape_uuid2 & (ape_text_paddr >> 12))); ape_uuid2 = ((ape_uuid2 | (ape_text_paddr << 25)) - (ape_uuid2 & (ape_text_paddr << 25))); ape_uuid2 = ((ape_uuid2 | (ape_text_paddr >> 27)) - (ape_uuid2 & (ape_text_paddr >> 27))); ape_uuid2 = (ape_uuid2 + (ape_text_paddr >> 000) & 0xFF) * 0x9e3779b9925d4c17; ape_uuid2 = (ape_uuid2 + (ape_text_paddr >> 010) & 0xFF) * 0x9e3779b9925d4c17; ape_uuid2 = (ape_uuid2 + (ape_text_paddr >> 020) & 0xFF) * 0x9e3779b9925d4c17; ape_uuid2 = (ape_uuid2 + (ape_text_paddr >> 030) & 0xFF) * 0x9e3779b9925d4c17;
ape_uuid1 = ((ape_uuid1 | (ape_text_rva >> 12)) - (ape_uuid1 & (ape_text_rva >> 12))); ape_uuid1 = ((ape_uuid1 | (ape_text_rva << 25)) - (ape_uuid1 & (ape_text_rva << 25))); ape_uuid1 = ((ape_uuid1 | (ape_text_rva >> 27)) - (ape_uuid1 & (ape_text_rva >> 27))); ape_uuid1 = (ape_uuid1 + (ape_text_rva >> 000) & 0xFF) * 0x9e3779b9925d4c17; ape_uuid1 = (ape_uuid1 + (ape_text_rva >> 010) & 0xFF) * 0x9e3779b9925d4c17; ape_uuid1 = (ape_uuid1 + (ape_text_rva >> 020) & 0xFF) * 0x9e3779b9925d4c17; ape_uuid1 = (ape_uuid1 + (ape_text_rva >> 030) & 0xFF) * 0x9e3779b9925d4c17; ape_uuid2 = ((ape_uuid2 | (ape_text_rva >> 12)) - (ape_uuid2 & (ape_text_rva >> 12))); ape_uuid2 = ((ape_uuid2 | (ape_text_rva << 25)) - (ape_uuid2 & (ape_text_rva << 25))); ape_uuid2 = ((ape_uuid2 | (ape_text_rva >> 27)) - (ape_uuid2 & (ape_text_rva >> 27))); ape_uuid2 = (ape_uuid2 + (ape_text_rva >> 000) & 0xFF) * 0x9e3779b9925d4c17; ape_uuid2 = (ape_uuid2 + (ape_text_rva >> 010) & 0xFF) * 0x9e3779b9925d4c17; ape_uuid2 = (ape_uuid2 + (ape_text_rva >> 020) & 0xFF) * 0x9e3779b9925d4c17; ape_uuid2 = (ape_uuid2 + (ape_text_rva >> 030) & 0xFF) * 0x9e3779b9925d4c17;
ape_uuid1 = ((ape_uuid1 | (ape_text_vaddr >> 12)) - (ape_uuid1 & (ape_text_vaddr >> 12))); ape_uuid1 = ((ape_uuid1 | (ape_text_vaddr << 25)) - (ape_uuid1 & (ape_text_vaddr << 25))); ape_uuid1 = ((ape_uuid1 | (ape_text_vaddr >> 27)) - (ape_uuid1 & (ape_text_vaddr >> 27))); ape_uuid1 = (ape_uuid1 + (ape_text_vaddr >> 000) & 0xFF) * 0x9e3779b9925d4c17; ape_uuid1 = (ape_uuid1 + (ape_text_vaddr >> 010) & 0xFF) * 0x9e3779b9925d4c17; ape_uuid1 = (ape_uuid1 + (ape_text_vaddr >> 020) & 0xFF) * 0x9e3779b9925d4c17; ape_uuid1 = (ape_uuid1 + (ape_text_vaddr >> 030) & 0xFF) * 0x9e3779b9925d4c17; ape_uuid2 = ((ape_uuid2 | (ape_text_vaddr >> 12)) - (ape_uuid2 & (ape_text_vaddr >> 12))); ape_uuid2 = ((ape_uuid2 | (ape_text_vaddr << 25)) - (ape_uuid2 & (ape_text_vaddr << 25))); ape_uuid2 = ((ape_uuid2 | (ape_text_vaddr >> 27)) - (ape_uuid2 & (ape_text_vaddr >> 27))); ape_uuid2 = (ape_uuid2 + (ape_text_vaddr >> 000) & 0xFF) * 0x9e3779b9925d4c17; ape_uuid2 = (ape_uuid2 + (ape_text_vaddr >> 010) & 0xFF) * 0x9e3779b9925d4c17; ape_uuid2 = (ape_uuid2 + (ape_text_vaddr >> 020) & 0xFF) * 0x9e3779b9925d4c17; ape_uuid2 = (ape_uuid2 + (ape_text_vaddr >> 030) & 0xFF) * 0x9e3779b9925d4c17;
ape_uuid1 = ((ape_uuid1 | (ADDR(.bss) >> 12)) - (ape_uuid1 & (ADDR(.bss) >> 12))); ape_uuid1 = ((ape_uuid1 | (ADDR(.bss) << 25)) - (ape_uuid1 & (ADDR(.bss) << 25))); ape_uuid1 = ((ape_uuid1 | (ADDR(.bss) >> 27)) - (ape_uuid1 & (ADDR(.bss) >> 27))); ape_uuid1 = (ape_uuid1 + (ADDR(.bss) >> 000) & 0xFF) * 0x9e3779b9925d4c17; ape_uuid1 = (ape_uuid1 + (ADDR(.bss) >> 010) & 0xFF) * 0x9e3779b9925d4c17; ape_uuid1 = (ape_uuid1 + (ADDR(.bss) >> 020) & 0xFF) * 0x9e3779b9925d4c17; ape_uuid1 = (ape_uuid1 + (ADDR(.bss) >> 030) & 0xFF) * 0x9e3779b9925d4c17; ape_uuid2 = ((ape_uuid2 | (ADDR(.bss) >> 12)) - (ape_uuid2 & (ADDR(.bss) >> 12))); ape_uuid2 = ((ape_uuid2 | (ADDR(.bss) << 25)) - (ape_uuid2 & (ADDR(.bss) << 25))); ape_uuid2 = ((ape_uuid2 | (ADDR(.bss) >> 27)) - (ape_uuid2 & (ADDR(.bss) >> 27))); ape_uuid2 = (ape_uuid2 + (ADDR(.bss) >> 000) & 0xFF) * 0x9e3779b9925d4c17; ape_uuid2 = (ape_uuid2 + (ADDR(.bss) >> 010) & 0xFF) * 0x9e3779b9925d4c17; ape_uuid2 = (ape_uuid2 + (ADDR(.bss) >> 020) & 0xFF) * 0x9e3779b9925d4c17; ape_uuid2 = (ape_uuid2 + (ADDR(.bss) >> 030) & 0xFF) * 0x9e3779b9925d4c17;
ape_uuid1 = ((ape_uuid1 | (_start >> 12)) - (ape_uuid1 & (_start >> 12))); ape_uuid1 = ((ape_uuid1 | (_start << 25)) - (ape_uuid1 & (_start << 25))); ape_uuid1 = ((ape_uuid1 | (_start >> 27)) - (ape_uuid1 & (_start >> 27))); ape_uuid1 = (ape_uuid1 + (_start >> 000) & 0xFF) * 0x9e3779b9925d4c17; ape_uuid1 = (ape_uuid1 + (_start >> 010) & 0xFF) * 0x9e3779b9925d4c17; ape_uuid1 = (ape_uuid1 + (_start >> 020) & 0xFF) * 0x9e3779b9925d4c17; ape_uuid1 = (ape_uuid1 + (_start >> 030) & 0xFF) * 0x9e3779b9925d4c17; ape_uuid2 = ((ape_uuid2 | (_start >> 12)) - (ape_uuid2 & (_start >> 12))); ape_uuid2 = ((ape_uuid2 | (_start << 25)) - (ape_uuid2 & (_start << 25))); ape_uuid2 = ((ape_uuid2 | (_start >> 27)) - (ape_uuid2 & (_start >> 27))); ape_uuid2 = (ape_uuid2 + (_start >> 000) & 0xFF) * 0x9e3779b9925d4c17; ape_uuid2 = (ape_uuid2 + (_start >> 010) & 0xFF) * 0x9e3779b9925d4c17; ape_uuid2 = (ape_uuid2 + (_start >> 020) & 0xFF) * 0x9e3779b9925d4c17; ape_uuid2 = (ape_uuid2 + (_start >> 030) & 0xFF) * 0x9e3779b9925d4c17;
ape_uuid1 = ((ape_uuid1 | (ape_phdrs >> 12)) - (ape_uuid1 & (ape_phdrs >> 12))); ape_uuid1 = ((ape_uuid1 | (ape_phdrs << 25)) - (ape_uuid1 & (ape_phdrs << 25))); ape_uuid1 = ((ape_uuid1 | (ape_phdrs >> 27)) - (ape_uuid1 & (ape_phdrs >> 27))); ape_uuid1 = (ape_uuid1 + (ape_phdrs >> 000) & 0xFF) * 0x9e3779b9925d4c17; ape_uuid1 = (ape_uuid1 + (ape_phdrs >> 010) & 0xFF) * 0x9e3779b9925d4c17; ape_uuid1 = (ape_uuid1 + (ape_phdrs >> 020) & 0xFF) * 0x9e3779b9925d4c17; ape_uuid1 = (ape_uuid1 + (ape_phdrs >> 030) & 0xFF) * 0x9e3779b9925d4c17; ape_uuid2 = ((ape_uuid2 | (ape_phdrs >> 12)) - (ape_uuid2 & (ape_phdrs >> 12))); ape_uuid2 = ((ape_uuid2 | (ape_phdrs << 25)) - (ape_uuid2 & (ape_phdrs << 25))); ape_uuid2 = ((ape_uuid2 | (ape_phdrs >> 27)) - (ape_uuid2 & (ape_phdrs >> 27))); ape_uuid2 = (ape_uuid2 + (ape_phdrs >> 000) & 0xFF) * 0x9e3779b9925d4c17; ape_uuid2 = (ape_uuid2 + (ape_phdrs >> 010) & 0xFF) * 0x9e3779b9925d4c17; ape_uuid2 = (ape_uuid2 + (ape_phdrs >> 020) & 0xFF) * 0x9e3779b9925d4c17; ape_uuid2 = (ape_uuid2 + (ape_phdrs >> 030) & 0xFF) * 0x9e3779b9925d4c17;
ape_uuid1 = ((ape_uuid1 | (v_ape_realsectors >> 12)) - (ape_uuid1 & (v_ape_realsectors >> 12))); ape_uuid1 = ((ape_uuid1 | (v_ape_realsectors << 25)) - (ape_uuid1 & (v_ape_realsectors << 25))); ape_uuid1 = ((ape_uuid1 | (v_ape_realsectors >> 27)) - (ape_uuid1 & (v_ape_realsectors >> 27))); ape_uuid1 = (ape_uuid1 + (v_ape_realsectors >> 000) & 0xFF) * 0x9e3779b9925d4c17; ape_uuid1 = (ape_uuid1 + (v_ape_realsectors >> 010) & 0xFF) * 0x9e3779b9925d4c17; ape_uuid1 = (ape_uuid1 + (v_ape_realsectors >> 020) & 0xFF) * 0x9e3779b9925d4c17; ape_uuid1 = (ape_uuid1 + (v_ape_realsectors >> 030) & 0xFF) * 0x9e3779b9925d4c17; ape_uuid2 = ((ape_uuid2 | (v_ape_realsectors >> 12)) - (ape_uuid2 & (v_ape_realsectors >> 12))); ape_uuid2 = ((ape_uuid2 | (v_ape_realsectors << 25)) - (ape_uuid2 & (v_ape_realsectors << 25))); ape_uuid2 = ((ape_uuid2 | (v_ape_realsectors >> 27)) - (ape_uuid2 & (v_ape_realsectors >> 27))); ape_uuid2 = (ape_uuid2 + (v_ape_realsectors >> 000) & 0xFF) * 0x9e3779b9925d4c17; ape_uuid2 = (ape_uuid2 + (v_ape_realsectors >> 010) & 0xFF) * 0x9e3779b9925d4c17; ape_uuid2 = (ape_uuid2 + (v_ape_realsectors >> 020) & 0xFF) * 0x9e3779b9925d4c17; ape_uuid2 = (ape_uuid2 + (v_ape_realsectors >> 030) & 0xFF) * 0x9e3779b9925d4c17;
ape_uuid1 = ((ape_uuid1 | (ape_macho >> 12)) - (ape_uuid1 & (ape_macho >> 12))); ape_uuid1 = ((ape_uuid1 | (ape_macho << 25)) - (ape_uuid1 & (ape_macho << 25))); ape_uuid1 = ((ape_uuid1 | (ape_macho >> 27)) - (ape_uuid1 & (ape_macho >> 27))); ape_uuid1 = (ape_uuid1 + (ape_macho >> 000) & 0xFF) * 0x9e3779b9925d4c17; ape_uuid1 = (ape_uuid1 + (ape_macho >> 010) & 0xFF) * 0x9e3779b9925d4c17; ape_uuid1 = (ape_uuid1 + (ape_macho >> 020) & 0xFF) * 0x9e3779b9925d4c17; ape_uuid1 = (ape_uuid1 + (ape_macho >> 030) & 0xFF) * 0x9e3779b9925d4c17; ape_uuid2 = ((ape_uuid2 | (ape_macho >> 12)) - (ape_uuid2 & (ape_macho >> 12))); ape_uuid2 = ((ape_uuid2 | (ape_macho << 25)) - (ape_uuid2 & (ape_macho << 25))); ape_uuid2 = ((ape_uuid2 | (ape_macho >> 27)) - (ape_uuid2 & (ape_macho >> 27))); ape_uuid2 = (ape_uuid2 + (ape_macho >> 000) & 0xFF) * 0x9e3779b9925d4c17; ape_uuid2 = (ape_uuid2 + (ape_macho >> 010) & 0xFF) * 0x9e3779b9925d4c17; ape_uuid2 = (ape_uuid2 + (ape_macho >> 020) & 0xFF) * 0x9e3779b9925d4c17; ape_uuid2 = (ape_uuid2 + (ape_macho >> 030) & 0xFF) * 0x9e3779b9925d4c17;
ape_uuid1 = ((ape_uuid1 | (ape_mz >> 12)) - (ape_uuid1 & (ape_mz >> 12))); ape_uuid1 = ((ape_uuid1 | (ape_mz << 25)) - (ape_uuid1 & (ape_mz << 25))); ape_uuid1 = ((ape_uuid1 | (ape_mz >> 27)) - (ape_uuid1 & (ape_mz >> 27))); ape_uuid1 = (ape_uuid1 + (ape_mz >> 000) & 0xFF) * 0x9e3779b9925d4c17; ape_uuid1 = (ape_uuid1 + (ape_mz >> 010) & 0xFF) * 0x9e3779b9925d4c17; ape_uuid1 = (ape_uuid1 + (ape_mz >> 020) & 0xFF) * 0x9e3779b9925d4c17; ape_uuid1 = (ape_uuid1 + (ape_mz >> 030) & 0xFF) * 0x9e3779b9925d4c17; ape_uuid2 = ((ape_uuid2 | (ape_mz >> 12)) - (ape_uuid2 & (ape_mz >> 12))); ape_uuid2 = ((ape_uuid2 | (ape_mz << 25)) - (ape_uuid2 & (ape_mz << 25))); ape_uuid2 = ((ape_uuid2 | (ape_mz >> 27)) - (ape_uuid2 & (ape_mz >> 27))); ape_uuid2 = (ape_uuid2 + (ape_mz >> 000) & 0xFF) * 0x9e3779b9925d4c17; ape_uuid2 = (ape_uuid2 + (ape_mz >> 010) & 0xFF) * 0x9e3779b9925d4c17; ape_uuid2 = (ape_uuid2 + (ape_mz >> 020) & 0xFF) * 0x9e3779b9925d4c17; ape_uuid2 = (ape_uuid2 + (ape_mz >> 030) & 0xFF) * 0x9e3779b9925d4c17;
ape_uuid1 = ((ape_uuid1 | (ape_pe >> 12)) - (ape_uuid1 & (ape_pe >> 12))); ape_uuid1 = ((ape_uuid1 | (ape_pe << 25)) - (ape_uuid1 & (ape_pe << 25))); ape_uuid1 = ((ape_uuid1 | (ape_pe >> 27)) - (ape_uuid1 & (ape_pe >> 27))); ape_uuid1 = (ape_uuid1 + (ape_pe >> 000) & 0xFF) * 0x9e3779b9925d4c17; ape_uuid1 = (ape_uuid1 + (ape_pe >> 010) & 0xFF) * 0x9e3779b9925d4c17; ape_uuid1 = (ape_uuid1 + (ape_pe >> 020) & 0xFF) * 0x9e3779b9925d4c17; ape_uuid1 = (ape_uuid1 + (ape_pe >> 030) & 0xFF) * 0x9e3779b9925d4c17; ape_uuid2 = ((ape_uuid2 | (ape_pe >> 12)) - (ape_uuid2 & (ape_pe >> 12))); ape_uuid2 = ((ape_uuid2 | (ape_pe << 25)) - (ape_uuid2 & (ape_pe << 25))); ape_uuid2 = ((ape_uuid2 | (ape_pe >> 27)) - (ape_uuid2 & (ape_pe >> 27))); ape_uuid2 = (ape_uuid2 + (ape_pe >> 000) & 0xFF) * 0x9e3779b9925d4c17; ape_uuid2 = (ape_uuid2 + (ape_pe >> 010) & 0xFF) * 0x9e3779b9925d4c17; ape_uuid2 = (ape_uuid2 + (ape_pe >> 020) & 0xFF) * 0x9e3779b9925d4c17; ape_uuid2 = (ape_uuid2 + (ape_pe >> 030) & 0xFF) * 0x9e3779b9925d4c17;
ape_uuid1 = ((ape_uuid1 | (ape_pe_offset >> 12)) - (ape_uuid1 & (ape_pe_offset >> 12))); ape_uuid1 = ((ape_uuid1 | (ape_pe_offset << 25)) - (ape_uuid1 & (ape_pe_offset << 25))); ape_uuid1 = ((ape_uuid1 | (ape_pe_offset >> 27)) - (ape_uuid1 & (ape_pe_offset >> 27))); ape_uuid1 = (ape_uuid1 + (ape_pe_offset >> 000) & 0xFF) * 0x9e3779b9925d4c17; ape_uuid1 = (ape_uuid1 + (ape_pe_offset >> 010) & 0xFF) * 0x9e3779b9925d4c17; ape_uuid1 = (ape_uuid1 + (ape_pe_offset >> 020) & 0xFF) * 0x9e3779b9925d4c17; ape_uuid1 = (ape_uuid1 + (ape_pe_offset >> 030) & 0xFF) * 0x9e3779b9925d4c17; ape_uuid2 = ((ape_uuid2 | (ape_pe_offset >> 12)) - (ape_uuid2 & (ape_pe_offset >> 12))); ape_uuid2 = ((ape_uuid2 | (ape_pe_offset << 25)) - (ape_uuid2 & (ape_pe_offset << 25))); ape_uuid2 = ((ape_uuid2 | (ape_pe_offset >> 27)) - (ape_uuid2 & (ape_pe_offset >> 27))); ape_uuid2 = (ape_uuid2 + (ape_pe_offset >> 000) & 0xFF) * 0x9e3779b9925d4c17; ape_uuid2 = (ape_uuid2 + (ape_pe_offset >> 010) & 0xFF) * 0x9e3779b9925d4c17; ape_uuid2 = (ape_uuid2 + (ape_pe_offset >> 020) & 0xFF) * 0x9e3779b9925d4c17; ape_uuid2 = (ape_uuid2 + (ape_pe_offset >> 030) & 0xFF) * 0x9e3779b9925d4c17;
ape_uuid1 = ((ape_uuid1 | (ape_pe_optsz >> 12)) - (ape_uuid1 & (ape_pe_optsz >> 12))); ape_uuid1 = ((ape_uuid1 | (ape_pe_optsz << 25)) - (ape_uuid1 & (ape_pe_optsz << 25))); ape_uuid1 = ((ape_uuid1 | (ape_pe_optsz >> 27)) - (ape_uuid1 & (ape_pe_optsz >> 27))); ape_uuid1 = (ape_uuid1 + (ape_pe_optsz >> 000) & 0xFF) * 0x9e3779b9925d4c17; ape_uuid1 = (ape_uuid1 + (ape_pe_optsz >> 010) & 0xFF) * 0x9e3779b9925d4c17; ape_uuid1 = (ape_uuid1 + (ape_pe_optsz >> 020) & 0xFF) * 0x9e3779b9925d4c17; ape_uuid1 = (ape_uuid1 + (ape_pe_optsz >> 030) & 0xFF) * 0x9e3779b9925d4c17; ape_uuid2 = ((ape_uuid2 | (ape_pe_optsz >> 12)) - (ape_uuid2 & (ape_pe_optsz >> 12))); ape_uuid2 = ((ape_uuid2 | (ape_pe_optsz << 25)) - (ape_uuid2 & (ape_pe_optsz << 25))); ape_uuid2 = ((ape_uuid2 | (ape_pe_optsz >> 27)) - (ape_uuid2 & (ape_pe_optsz >> 27))); ape_uuid2 = (ape_uuid2 + (ape_pe_optsz >> 000) & 0xFF) * 0x9e3779b9925d4c17; ape_uuid2 = (ape_uuid2 + (ape_pe_optsz >> 010) & 0xFF) * 0x9e3779b9925d4c17; ape_uuid2 = (ape_uuid2 + (ape_pe_optsz >> 020) & 0xFF) * 0x9e3779b9925d4c17; ape_uuid2 = (ape_uuid2 + (ape_pe_optsz >> 030) & 0xFF) * 0x9e3779b9925d4c17;
ape_uuid1 = ((ape_uuid1 | (ape_pe_sections >> 12)) - (ape_uuid1 & (ape_pe_sections >> 12))); ape_uuid1 = ((ape_uuid1 | (ape_pe_sections << 25)) - (ape_uuid1 & (ape_pe_sections << 25))); ape_uuid1 = ((ape_uuid1 | (ape_pe_sections >> 27)) - (ape_uuid1 & (ape_pe_sections >> 27))); ape_uuid1 = (ape_uuid1 + (ape_pe_sections >> 000) & 0xFF) * 0x9e3779b9925d4c17; ape_uuid1 = (ape_uuid1 + (ape_pe_sections >> 010) & 0xFF) * 0x9e3779b9925d4c17; ape_uuid1 = (ape_uuid1 + (ape_pe_sections >> 020) & 0xFF) * 0x9e3779b9925d4c17; ape_uuid1 = (ape_uuid1 + (ape_pe_sections >> 030) & 0xFF) * 0x9e3779b9925d4c17; ape_uuid2 = ((ape_uuid2 | (ape_pe_sections >> 12)) - (ape_uuid2 & (ape_pe_sections >> 12))); ape_uuid2 = ((ape_uuid2 | (ape_pe_sections << 25)) - (ape_uuid2 & (ape_pe_sections << 25))); ape_uuid2 = ((ape_uuid2 | (ape_pe_sections >> 27)) - (ape_uuid2 & (ape_pe_sections >> 27))); ape_uuid2 = (ape_uuid2 + (ape_pe_sections >> 000) & 0xFF) * 0x9e3779b9925d4c17; ape_uuid2 = (ape_uuid2 + (ape_pe_sections >> 010) & 0xFF) * 0x9e3779b9925d4c17; ape_uuid2 = (ape_uuid2 + (ape_pe_sections >> 020) & 0xFF) * 0x9e3779b9925d4c17; ape_uuid2 = (ape_uuid2 + (ape_pe_sections >> 030) & 0xFF) * 0x9e3779b9925d4c17;
ape_uuid1 = ((ape_uuid1 | (ape_pe_sections_end >> 12)) - (ape_uuid1 & (ape_pe_sections_end >> 12))); ape_uuid1 = ((ape_uuid1 | (ape_pe_sections_end << 25)) - (ape_uuid1 & (ape_pe_sections_end << 25))); ape_uuid1 = ((ape_uuid1 | (ape_pe_sections_end >> 27)) - (ape_uuid1 & (ape_pe_sections_end >> 27))); ape_uuid1 = (ape_uuid1 + (ape_pe_sections_end >> 000) & 0xFF) * 0x9e3779b9925d4c17; ape_uuid1 = (ape_uuid1 + (ape_pe_sections_end >> 010) & 0xFF) * 0x9e3779b9925d4c17; ape_uuid1 = (ape_uuid1 + (ape_pe_sections_end >> 020) & 0xFF) * 0x9e3779b9925d4c17; ape_uuid1 = (ape_uuid1 + (ape_pe_sections_end >> 030) & 0xFF) * 0x9e3779b9925d4c17; ape_uuid2 = ((ape_uuid2 | (ape_pe_sections_end >> 12)) - (ape_uuid2 & (ape_pe_sections_end >> 12))); ape_uuid2 = ((ape_uuid2 | (ape_pe_sections_end << 25)) - (ape_uuid2 & (ape_pe_sections_end << 25))); ape_uuid2 = ((ape_uuid2 | (ape_pe_sections_end >> 27)) - (ape_uuid2 & (ape_pe_sections_end >> 27))); ape_uuid2 = (ape_uuid2 + (ape_pe_sections_end >> 000) & 0xFF) * 0x9e3779b9925d4c17; ape_uuid2 = (ape_uuid2 + (ape_pe_sections_end >> 010) & 0xFF) * 0x9e3779b9925d4c17; ape_uuid2 = (ape_uuid2 + (ape_pe_sections_end >> 020) & 0xFF) * 0x9e3779b9925d4c17; ape_uuid2 = (ape_uuid2 + (ape_pe_sections_end >> 030) & 0xFF) * 0x9e3779b9925d4c17;
ape_uuid1 = ((ape_uuid1 | (ape_pe_shnum >> 12)) - (ape_uuid1 & (ape_pe_shnum >> 12))); ape_uuid1 = ((ape_uuid1 | (ape_pe_shnum << 25)) - (ape_uuid1 & (ape_pe_shnum << 25))); ape_uuid1 = ((ape_uuid1 | (ape_pe_shnum >> 27)) - (ape_uuid1 & (ape_pe_shnum >> 27))); ape_uuid1 = (ape_uuid1 + (ape_pe_shnum >> 000) & 0xFF) * 0x9e3779b9925d4c17; ape_uuid1 = (ape_uuid1 + (ape_pe_shnum >> 010) & 0xFF) * 0x9e3779b9925d4c17; ape_uuid1 = (ape_uuid1 + (ape_pe_shnum >> 020) & 0xFF) * 0x9e3779b9925d4c17; ape_uuid1 = (ape_uuid1 + (ape_pe_shnum >> 030) & 0xFF) * 0x9e3779b9925d4c17; ape_uuid2 = ((ape_uuid2 | (ape_pe_shnum >> 12)) - (ape_uuid2 & (ape_pe_shnum >> 12))); ape_uuid2 = ((ape_uuid2 | (ape_pe_shnum << 25)) - (ape_uuid2 & (ape_pe_shnum << 25))); ape_uuid2 = ((ape_uuid2 | (ape_pe_shnum >> 27)) - (ape_uuid2 & (ape_pe_shnum >> 27))); ape_uuid2 = (ape_uuid2 + (ape_pe_shnum >> 000) & 0xFF) * 0x9e3779b9925d4c17; ape_uuid2 = (ape_uuid2 + (ape_pe_shnum >> 010) & 0xFF) * 0x9e3779b9925d4c17; ape_uuid2 = (ape_uuid2 + (ape_pe_shnum >> 020) & 0xFF) * 0x9e3779b9925d4c17; ape_uuid2 = (ape_uuid2 + (ape_pe_shnum >> 030) & 0xFF) * 0x9e3779b9925d4c17;
ape_uuid1 = ((ape_uuid1 | (ape_phdrs_end >> 12)) - (ape_uuid1 & (ape_phdrs_end >> 12))); ape_uuid1 = ((ape_uuid1 | (ape_phdrs_end << 25)) - (ape_uuid1 & (ape_phdrs_end << 25))); ape_uuid1 = ((ape_uuid1 | (ape_phdrs_end >> 27)) - (ape_uuid1 & (ape_phdrs_end >> 27))); ape_uuid1 = (ape_uuid1 + (ape_phdrs_end >> 000) & 0xFF) * 0x9e3779b9925d4c17; ape_uuid1 = (ape_uuid1 + (ape_phdrs_end >> 010) & 0xFF) * 0x9e3779b9925d4c17; ape_uuid1 = (ape_uuid1 + (ape_phdrs_end >> 020) & 0xFF) * 0x9e3779b9925d4c17; ape_uuid1 = (ape_uuid1 + (ape_phdrs_end >> 030) & 0xFF) * 0x9e3779b9925d4c17; ape_uuid2 = ((ape_uuid2 | (ape_phdrs_end >> 12)) - (ape_uuid2 & (ape_phdrs_end >> 12))); ape_uuid2 = ((ape_uuid2 | (ape_phdrs_end << 25)) - (ape_uuid2 & (ape_phdrs_end << 25))); ape_uuid2 = ((ape_uuid2 | (ape_phdrs_end >> 27)) - (ape_uuid2 & (ape_phdrs_end >> 27))); ape_uuid2 = (ape_uuid2 + (ape_phdrs_end >> 000) & 0xFF) * 0x9e3779b9925d4c17; ape_uuid2 = (ape_uuid2 + (ape_phdrs_end >> 010) & 0xFF) * 0x9e3779b9925d4c17; ape_uuid2 = (ape_uuid2 + (ape_phdrs_end >> 020) & 0xFF) * 0x9e3779b9925d4c17; ape_uuid2 = (ape_uuid2 + (ape_phdrs_end >> 030) & 0xFF) * 0x9e3779b9925d4c17;
ape_uuid1 = ((ape_uuid1 | (WinMain >> 12)) - (ape_uuid1 & (WinMain >> 12))); ape_uuid1 = ((ape_uuid1 | (WinMain << 25)) - (ape_uuid1 & (WinMain << 25))); ape_uuid1 = ((ape_uuid1 | (WinMain >> 27)) - (ape_uuid1 & (WinMain >> 27))); ape_uuid1 = (ape_uuid1 + (WinMain >> 000) & 0xFF) * 0x9e3779b9925d4c17; ape_uuid1 = (ape_uuid1 + (WinMain >> 010) & 0xFF) * 0x9e3779b9925d4c17; ape_uuid1 = (ape_uuid1 + (WinMain >> 020) & 0xFF) * 0x9e3779b9925d4c17; ape_uuid1 = (ape_uuid1 + (WinMain >> 030) & 0xFF) * 0x9e3779b9925d4c17; ape_uuid2 = ((ape_uuid2 | (WinMain >> 12)) - (ape_uuid2 & (WinMain >> 12))); ape_uuid2 = ((ape_uuid2 | (WinMain << 25)) - (ape_uuid2 & (WinMain << 25))); ape_uuid2 = ((ape_uuid2 | (WinMain >> 27)) - (ape_uuid2 & (WinMain >> 27))); ape_uuid2 = (ape_uuid2 + (WinMain >> 000) & 0xFF) * 0x9e3779b9925d4c17; ape_uuid2 = (ape_uuid2 + (WinMain >> 010) & 0xFF) * 0x9e3779b9925d4c17; ape_uuid2 = (ape_uuid2 + (WinMain >> 020) & 0xFF) * 0x9e3779b9925d4c17; ape_uuid2 = (ape_uuid2 + (WinMain >> 030) & 0xFF) * 0x9e3779b9925d4c17;
ASSERT(DEFINED(ape_mz) ? ape_mz == 0x400000 : 1, "linker panic");
ASSERT((DEFINED(__init_bss_end) ? __init_bss_end : 0) % 8 == 0,
       "__init_bss misalign");
ASSERT(((DEFINED(__init_rodata_end) ? __init_rodata_end : 0) %
        8 == 0),
       "__init_rodata misalign");
ASSERT((!DEFINED(ape_grub) ? 1 : ((ape_grub) - (0x400000)) < 8192),
       "grub stub needs to be in first 8kb of image");
ASSERT(DEFINED(_start) || DEFINED(_start16),
       "please link a _start() or _start16() entrypoint");
ASSERT(!DEFINED(_start16) || ((_end) - (0x400000 - 0x2000)) < 65536,
       "ape won't support non-tiny real mode programs");
